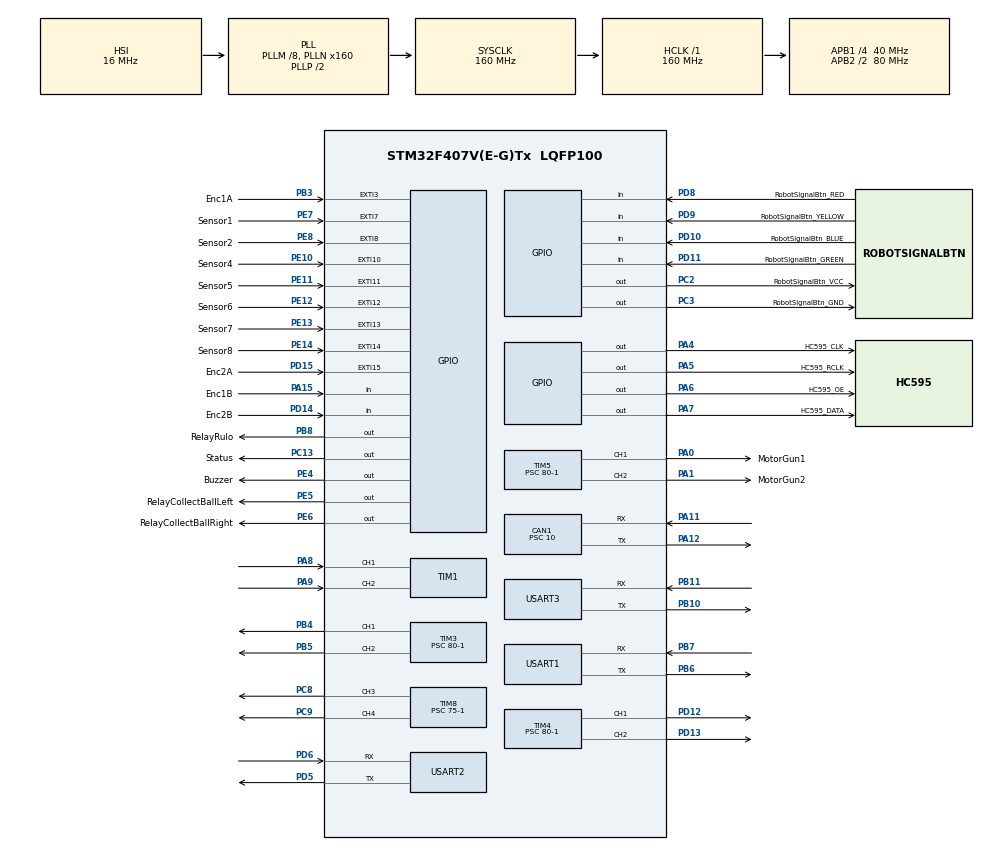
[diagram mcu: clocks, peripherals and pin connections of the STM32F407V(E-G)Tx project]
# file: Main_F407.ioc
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CAN1.BS1=CAN_BS1_2TQ
CAN1.CalculateBaudRate=1000000
CAN1.CalculateTimeBit=1000
CAN1.CalculateTimeQuantum=250.0
CAN1.Prescaler=10
Dma.Request0=USART1_RX
Dma.USART1_RX.0.Direction=DMA_PERIPH_TO_MEMORY
Dma.USART1_RX.0.FIFOMode=DMA_FIFOMODE_DISABLE
Dma.USART1_RX.0.Instance=DMA2_Stream2
Dma.USART1_RX.0.MemDataAlignment=DMA_MDATAALIGN_BYTE
Dma.USART1_RX.0.MemInc=DMA_MINC_ENABLE
Dma.USART1_RX.0.Mode=DMA_CIRCULAR
Dma.USART1_RX.0.PeriphDataAlignment=DMA_PDATAALIGN_BYTE
Dma.USART1_RX.0.PeriphInc=DMA_PINC_DISABLE
Dma.USART1_RX.0.Priority=DMA_PRIORITY_LOW
FREERTOS.Tasks01=defaultTask,-3,256,StartDefaultTask,Default,NULL,Dynamic,NULL,NULL;TaskInvKine,0,256,InverseKinematic,Default,NULL,Static,TaskInvKineBuffer,TaskInvKineControlBlock;TaskCAN,1,128,CAN_Bus,Default,NULL,Static,TaskCANBuffer,TaskCANControlBlock;TaskActuator,1,128,Actuator,Default,NULL,Dynamic,NULL,NULL;TaskOdometer,0,128,OdometerHandle,Default,NULL,Dynamic,NULL,NULL;TaskProcess,0,256,TaskRunProcess,Default,NULL,Dynamic,NULL,NULL
FREERTOS.configMINIMAL_STACK_SIZE=64
FREERTOS.configUSE_NEWLIB_REENTRANT=1
Mcu.Family=STM32F4
Mcu.Name=STM32F407V(E-G)Tx
Mcu.Package=LQFP100
NVIC.CAN1_RX0_IRQn=true\:5\:0\:false\:false\:true\:true\:true\:true\:true
NVIC.DMA2_Stream2_IRQn=true\:5\:0\:false\:false\:true\:true\:false\:true\:true
NVIC.EXTI15_10_IRQn=true\:5\:0\:false\:false\:true\:true\:true\:true\:true
NVIC.EXTI3_IRQn=true\:5\:0\:false\:false\:true\:true\:true\:true\:true
NVIC.EXTI9_5_IRQn=true\:5\:0\:false\:false\:true\:true\:true\:true\:true
NVIC.PriorityGroup=NVIC_PRIORITYGROUP_4
NVIC.TIM8_TRG_COM_TIM14_IRQn=true\:5\:0\:false\:false\:true\:false\:false\:true\:true
NVIC.TimeBase=TIM8_TRG_COM_TIM14_IRQn
NVIC.TimeBaseIP=TIM14
NVIC.USART1_IRQn=true\:5\:0\:false\:false\:true\:true\:true\:true\:true
NVIC.USART2_IRQn=true\:5\:0\:false\:false\:true\:true\:true\:true\:true
NVIC.USART3_IRQn=true\:5\:0\:false\:false\:true\:true\:true\:true\:true
PA0-WKUP.GPIO_Label=MotorGun1
PA0-WKUP.Signal=S_TIM5_CH1
PA1.GPIO_Label=MotorGun2
PA1.Signal=S_TIM5_CH2
PA11.Mode=CAN_Activate
PA11.Signal=CAN1_RX
PA12.Mode=CAN_Activate
PA12.Signal=CAN1_TX
PA13.Mode=Serial_Wire
PA13.Signal=SYS_JTMS-SWDIO
PA14.Mode=Serial_Wire
PA14.Signal=SYS_JTCK-SWCLK
PA15.GPIO_Label=Enc1B
PA15.GPIO_PuPd=GPIO_PULLUP
PA15.Signal=GPIO_Input
PA4.GPIO_Label=HC595_CLK
PA4.Signal=GPIO_Output
PA5.GPIO_Label=HC595_RCLK
PA5.Signal=GPIO_Output
PA6.GPIO_Label=HC595_OE
PA6.Signal=GPIO_Output
PA7.GPIO_Label=HC595_DATA
PA7.Signal=GPIO_Output
PA8.Signal=S_TIM1_CH1
PA9.Signal=S_TIM1_CH2
PB10.Mode=Asynchronous
PB10.Signal=USART3_TX
PB11.Mode=Asynchronous
PB11.Signal=USART3_RX
PB3.GPIO_Label=Enc1A
PB3.GPIO_ModeDefaultEXTI=GPIO_MODE_IT_RISING
PB3.GPIO_PuPd=GPIO_PULLUP
PB3.Signal=GPXTI3
PB4.Signal=S_TIM3_CH1
PB5.Signal=S_TIM3_CH2
PB6.Mode=Asynchronous
PB6.Signal=USART1_TX
PB7.Mode=Asynchronous
PB7.Signal=USART1_RX
PB8.GPIO_Label=RelayRulo
PB8.Signal=GPIO_Output
PC13-ANTI_TAMP.GPIO_Label=Status
PC13-ANTI_TAMP.Signal=GPIO_Output
PC2.GPIO_Label=RobotSignalBtn_VCC
PC2.Signal=GPIO_Output
PC3.GPIO_Label=RobotSignalBtn_GND
PC3.Signal=GPIO_Output
PC8.Signal=S_TIM8_CH3
PC9.Signal=S_TIM8_CH4
PD10.GPIO_Label=RobotSignalBtn_BLUE
PD10.Signal=GPIO_Input
PD11.GPIO_Label=RobotSignalBtn_GREEN
PD11.Signal=GPIO_Input
PD12.Signal=S_TIM4_CH1
PD13.Signal=S_TIM4_CH2
PD14.GPIO_Label=Enc2B
PD14.GPIO_PuPd=GPIO_PULLUP
PD14.Signal=GPIO_Input
PD15.GPIO_Label=Enc2A
PD15.GPIO_PuPd=GPIO_PULLUP
PD15.Signal=GPXTI15
PD5.Mode=Asynchronous
PD5.Signal=USART2_TX
PD6.Mode=Asynchronous
PD6.Signal=USART2_RX
PD8.GPIO_Label=RobotSignalBtn_RED
PD8.Signal=GPIO_Input
PD9.GPIO_Label=RobotSignalBtn_YELLOW
PD9.Signal=GPIO_Input
PE10.GPIO_Label=Sensor4
PE10.Signal=GPXTI10
PE11.GPIO_Label=Sensor5
PE11.Signal=GPXTI11
PE12.GPIO_Label=Sensor6
PE12.Signal=GPXTI12
PE13.GPIO_Label=Sensor7
PE13.Signal=GPXTI13
PE14.GPIO_Label=Sensor8
PE14.Signal=GPXTI14
PE4.GPIO_Label=Buzzer
PE4.Signal=GPIO_Output
PE5.GPIO_Label=RelayCollectBallLeft
PE5.Signal=GPIO_Output
PE6.GPIO_Label=RelayCollectBallRight
PE6.Signal=GPIO_Output
PE7.GPIO_Label=Sensor1
PE7.Signal=GPXTI7
PE8.GPIO_Label=Sensor2
PE8.Signal=GPXTI8
ProjectManager.HeapSize=0x200
ProjectManager.StackSize=0x400
ProjectManager.TargetToolchain=STM32CubeIDE
RCC.48MHZClocksFreq_Value=80000000
RCC.AHBFreq_Value=160000000
RCC.APB1CLKDivider=RCC_HCLK_DIV4
RCC.APB1Freq_Value=40000000
RCC.APB1TimFreq_Value=80000000
RCC.APB2CLKDivider=RCC_HCLK_DIV2
RCC.APB2Freq_Value=80000000
RCC.APB2TimFreq_Value=160000000
RCC.CortexFreq_Value=160000000
RCC.HCLKFreq_Value=160000000
RCC.HSE_VALUE=8000000
RCC.HSI_VALUE=16000000
RCC.LSE_VALUE=32768
RCC.PLLM=8
RCC.PLLN=160
RCC.SYSCLKFreq_VALUE=160000000
RCC.SYSCLKSource=RCC_SYSCLKSOURCE_PLLCLK
RCC.VCOOutputFreq_Value=320000000
SH.S_TIM1_CH1.0=TIM1_CH1,Encoder_Interface
SH.S_TIM1_CH2.0=TIM1_CH2,Encoder_Interface
SH.S_TIM3_CH1.0=TIM3_CH1,PWM Generation1 CH1
SH.S_TIM3_CH2.0=TIM3_CH2,PWM Generation2 CH2
SH.S_TIM4_CH1.0=TIM4_CH1,PWM Generation1 CH1
SH.S_TIM4_CH2.0=TIM4_CH2,PWM Generation2 CH2
SH.S_TIM5_CH1.0=TIM5_CH1,PWM Generation1 CH1
SH.S_TIM5_CH2.0=TIM5_CH2,PWM Generation2 CH2
SH.S_TIM8_CH3.0=TIM8_CH3,PWM Generation3 CH3
SH.S_TIM8_CH4.0=TIM8_CH4,PWM Generation4 CH4
TIM1.EncoderMode=TIM_ENCODERMODE_TI12
TIM10.Period=65000
TIM10.Prescaler=160-1
TIM3.Channel-PWM\ Generation1\ CH1=TIM_CHANNEL_1
TIM3.Channel-PWM\ Generation2\ CH2=TIM_CHANNEL_2
TIM3.Period=1000-1
TIM3.Prescaler=80-1
TIM4.Channel-PWM\ Generation1\ CH1=TIM_CHANNEL_1
TIM4.Channel-PWM\ Generation2\ CH2=TIM_CHANNEL_2
TIM4.Period=1000-1
TIM4.Prescaler=80-1
TIM5.Channel-PWM\ Generation1\ CH1=TIM_CHANNEL_1
TIM5.Channel-PWM\ Generation2\ CH2=TIM_CHANNEL_2
TIM5.Period=1000-1
TIM5.Prescaler=80-1
TIM8.Channel-PWM\ Generation3\ CH3=TIM_CHANNEL_3
TIM8.Channel-PWM\ Generation4\ CH4=TIM_CHANNEL_4
TIM8.Period=255-1
TIM8.Prescaler=75-1
TIM9.Period=255-1
TIM9.Prescaler=75-1
USART1.VirtualMode=VM_ASYNC
USART2.VirtualMode=VM_ASYNC
USART3.VirtualMode=VM_ASYNC
VP_FREERTOS_VS_CMSIS_V1.Mode=CMSIS_V1
VP_SYS_VS_tim14.Mode=TIM14
VP_TIM10_VS_ClockSourceINT.Mode=Enable_Timer
VP_TIM3_VS_ClockSourceINT.Mode=Internal
VP_TIM4_VS_ClockSourceINT.Mode=Internal
VP_TIM5_VS_ClockSourceINT.Mode=Internal
VP_TIM8_VS_ClockSourceINT.Mode=Internal
VP_TIM9_VS_ClockSourceINT.Mode=Internal
board=custom

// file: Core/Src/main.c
/* USER CODE BEGIN Header */
/**
 ******************************************************************************
 * @file           : main.c
 * @brief          : Main program body
 ******************************************************************************
 * @attention
 *
 * Copyright (c) 2023 STMicroelectronics.
 * All rights reserved.
 *
 * This software is licensed under terms that can be found in the LICENSE file
 * in the root directory of this software component.
 * If no LICENSE file comes with this software, it is provided AS-IS.
 *
 ******************************************************************************
 */
/* USER CODE END Header */
#include "main.h"
#include "cmsis_os.h"

/* USER CODE BEGIN Includes */
#include "CAN_Control.h"
#include "CAN_FuncHandle.h"
#include "stdbool.h"
#include "PID.h"
#include "Flag.h"
#include "InverseKinematic.h"
#include "SwerveModule.h"
#include "string.h"
#include "Gamepad.h"
#include "RB1ActuatorValve.h"
#include "MainF4Robot1App.h"
#include "ActuatorGun.h"
#include "Robot1_Sensor.h"
#include "Robot1_InShootBallTime.h"
#include "PositionControl.h"
#include "Encoder.h"
/* USER CODE END Includes */

/* USER CODE BEGIN PTD */
typedef enum MainEvent {
	MEVT_GET_NODE_SPEED_ANGLE,
} MainEvent;
/* USER CODE END PTD */

CAN_HandleTypeDef hcan1;

TIM_HandleTypeDef htim1;
TIM_HandleTypeDef htim3;
TIM_HandleTypeDef htim4;
TIM_HandleTypeDef htim5;
TIM_HandleTypeDef htim8;
TIM_HandleTypeDef htim9;
TIM_HandleTypeDef htim10;

UART_HandleTypeDef huart1;
UART_HandleTypeDef huart2;
UART_HandleTypeDef huart3;
DMA_HandleTypeDef hdma_usart1_rx;

osThreadId defaultTaskHandle;
osThreadId TaskInvKineHandle;
uint32_t TaskInvKineBuffer[ 256 ];
osStaticThreadDef_t TaskInvKineControlBlock;
osThreadId TaskCANHandle;
uint32_t TaskCANBuffer[ 128 ];
osStaticThreadDef_t TaskCANControlBlock;
osThreadId TaskActuatorHandle;
osThreadId TaskOdometerHandle;
osThreadId TaskProcessHandle;
/* USER CODE BEGIN PV */

CAN_DEVICE_ID targetID = CANCTRL_DEVICE_MOTOR_CONTROLLER_1;
PID_Param pid;
PID_type type = PID_BLDC_SPEED;

CAN_MODE_ID Mode_ID = CANCTRL_MODE_MOTOR_SPEED_ANGLE;
PID_Param targetPID = {
		.deltaT = 0.001,
		.kP = 10,
		.kI = 10,
		.kD = 1,
		.alpha = 1,
};
PID_type pidType = PID_BLDC_SPEED;
uint8_t encEnb, encDis;
CAN_SpeedBLDC_AngleDC nodeSpeedAngle[3] = { 0 };

uint8_t UARTRX3_Buffer[9];
uint8_t DataTayGame[9];

float Xleft, Yleft;
float Xright;

_GamePad GamePad;
uint32_t gamepadRxIsBusy = 0;

float DeltaYR, DeltaYL, DeltaX;
uint8_t Run = 0, resetParam, breakProtect;
float uControlX, uControlY, uControlTheta;
uint8_t stateRun = 0, steadycheck;
uint8_t xaDay;
uint8_t ssCheck, stateChange, rst, Manual;
uint8_t numOfBall = 0;
bool safetyMode = false;
//////////////////////////////////////////////////////////////////////////////////////////////////////////

uint8_t step = 0;
uint8_t angle_PID_Cycle;
////////////MPU//////////////
uint8_t mpu[10];
uint8_t send_mpu;
int16_t angle;
float a_Now;
float angle_Rad;
uint8_t reset_MPU;

///////////PID MPU///////////////
PID_Param pid_Angle;
uint8_t use_pidTheta;
float TargetTheta, TargetTheta_Degree;
//////////Floating Enc///////
uint8_t reset_ENC;
Encoder_t FloatingEnc;
int floatingEncCount;

//////////Control Signal/////
float u, v, r;

//////////Process ///////////
uint8_t RunProcess;
float chasis_Vector_TargetSpeed;
uint8_t angle_Accel_Flag;
float PreTargetAngle;
float process_AutoChose;
float process_AutoChose_Count;
float process_SubState;
uint8_t process_GetBall_State;
uint8_t process_SSCheck;
int process_Count;
ValveProcessName valveProcessName = 0;
int PlusControl;
float V_want = 0;
uint8_t Blue = 0, Red = 0, Retry = 0;
///////////////////////////////////////Quy Hoach Quy Dao///////////////////////////////////////////
trajec_Param trajecTheta;
//////////////////////////////////////////////////////////////////////////////////////////////////////////

uint32_t nodeSwerveSetHomeComplete = 0;
int gunCount1, gunCount2;
QueueHandle_t qShoot;
bool testTick = false;

#define SETHOME_FLAG_GROUP nodeSwerveSetHomeComplete
void nodeHome_SetFlag(CAN_DEVICE_ID e) {
	SETFLAG(SETHOME_FLAG_GROUP, e);
}
bool nodeHome_CheckFlag(CAN_DEVICE_ID e) {
	return CHECKFLAG(SETHOME_FLAG_GROUP, e);
}
void nodeHome_ClearFlag(CAN_DEVICE_ID e) {
	CLEARFLAG(SETHOME_FLAG_GROUP, e);
}

/* USER CODE END PV */

void SystemClock_Config(void);
static void MX_GPIO_Init(void);
static void MX_DMA_Init(void);
static void MX_CAN1_Init(void);
static void MX_USART3_UART_Init(void);
static void MX_TIM1_Init(void);
static void MX_TIM10_Init(void);
static void MX_USART1_UART_Init(void);
static void MX_USART2_UART_Init(void);
static void MX_TIM5_Init(void);
static void MX_TIM9_Init(void);
static void MX_TIM4_Init(void);
static void MX_TIM3_Init(void);
static void MX_TIM8_Init(void);
void StartDefaultTask(void const * argument);
void InverseKinematic(void const * argument);
void CAN_Bus(void const * argument);
void Actuator(void const * argument);
void OdometerHandle(void const * argument);
void TaskRunProcess(void const * argument);

/* USER CODE BEGIN 0 */

/*=============================== CAN ===============================*/
void HAL_CAN_RxFifo0MsgPendingCallback(CAN_HandleTypeDef *hcan) {
	HAL_CAN_DeactivateNotification(hcan, CAN_IT_RX_FIFO0_MSG_PENDING);
	CAN_MODE_ID modeID = canctrl_Receive_2(hcan, CAN_RX_FIFO0);
	BaseType_t HigherPriorityTaskWoken = pdFALSE;
	xTaskNotifyFromISR(TaskCANHandle, modeID, eSetValueWithOverwrite, &HigherPriorityTaskWoken);
	portYIELD_FROM_ISR(HigherPriorityTaskWoken);
}
void HAL_CAN_RxFifo1MsgPendingCallback(CAN_HandleTypeDef *hcan) {
	HAL_CAN_DeactivateNotification(hcan, CAN_IT_RX_FIFO1_MSG_PENDING);
	CAN_MODE_ID modeID = canctrl_Receive_2(hcan, CAN_RX_FIFO1);
	BaseType_t HigherPriorityTaskWoken = pdFALSE;
	xTaskNotifyFromISR(TaskCANHandle, modeID, eSetValueWithOverwrite, &HigherPriorityTaskWoken);
	portYIELD_FROM_ISR(HigherPriorityTaskWoken);
}
void CAN_Init() {
	HAL_CAN_Start(&hcan1);
	HAL_CAN_ActivateNotification(&hcan1,
	CAN_IT_RX_FIFO0_MSG_PENDING | CAN_IT_RX_FIFO1_MSG_PENDING);
	canctrl_Filter_Mask16(&hcan1, CANCTRL_MODE_SET_HOME << 5,
			CANCTRL_MODE_ROBOT_ERROR << 5,
			CANCTRL_MODE_SET_HOME << 5,
			CANCTRL_MODE_ROBOT_ERROR << 5, 0,
			CAN_RX_FIFO0);
}

void setHomeComplete() {
	HAL_GPIO_WritePin(Buzzer_GPIO_Port, Buzzer_Pin, GPIO_PIN_SET);
	osDelay(100);
	HAL_GPIO_WritePin(Buzzer_GPIO_Port, Buzzer_Pin, GPIO_PIN_RESET);
}

void robotErrorHandler(CAN_DEVICE_ID targetID)
{

	while(1){
		safetyMode = 1;
		if(targetID == CANCTRL_DEVICE_MOTOR_CONTROLLER_1){
			HAL_GPIO_WritePin(Buzzer_GPIO_Port, Buzzer_Pin, 1);
			osDelay(50);
			HAL_GPIO_WritePin(Buzzer_GPIO_Port, Buzzer_Pin, 0);
			osDelay(1000);
		}
		else if(targetID == CANCTRL_DEVICE_MOTOR_CONTROLLER_2){
			for(uint8_t i = 0; i < 2; i++){
				HAL_GPIO_WritePin(Buzzer_GPIO_Port, Buzzer_Pin, 1);
				osDelay(100);
				HAL_GPIO_WritePin(Buzzer_GPIO_Port, Buzzer_Pin, 0);
			}
			osDelay(1000);
		}
		else if(targetID == CANCTRL_DEVICE_MOTOR_CONTROLLER_3){
			for(uint8_t i = 0; i < 3; i++){
				HAL_GPIO_WritePin(Buzzer_GPIO_Port, Buzzer_Pin, 1);
				osDelay(100);
				HAL_GPIO_WritePin(Buzzer_GPIO_Port, Buzzer_Pin, 0);
			}
			osDelay(1000);
		}
	}
}

void handleFunctionCAN(CAN_MODE_ID mode, CAN_DEVICE_ID targetID) {
	switch (mode) {
		case CANCTRL_MODE_SET_HOME:
			nodeHome_SetFlag(targetID);
			// @formatter:off
//			if(nodeHome_CheckFlag(
//					  1 << CANCTRL_DEVICE_MOTOR_CONTROLLER_1
//					| 1 << CANCTRL_DEVICE_MOTOR_CONTROLLER_2
//					| 1 << CANCTRL_DEVICE_MOTOR_CONTROLLER_3
//					| 1 << CANCTRL_DEVICE_MOTOR_CONTROLLER_4
//					))
			if(nodeSwerveSetHomeComplete == 14)
				setHomeComplete();
																		// @formatter:on
			break;
		case CANCTRL_MODE_ROBOT_ERROR:
			robotErrorHandler(targetID);
			break;
		case CANCTRL_MODE_UNTANGLE_WIRE:
			canfunc_SetBoolValue(1, CANCTRL_MODE_UNTANGLE_WIRE);
			while (canctrl_Send(&hcan1, targetID) != HAL_OK);
			break;
		default:
			break;
	}

}

void HAL_CAN_ErrorCallback(CAN_HandleTypeDef *hcan) {
	HAL_GPIO_WritePin(Buzzer_GPIO_Port, Buzzer_Pin, GPIO_PIN_SET);
	while (1);
}
/*=============================== UART ===============================*/
uint8_t YawHandle;
uint8_t AngleData[5];
int CurrAngle;

char ds[12];
uint8_t uart2_ds[5], ds_ind, ds_cnt, ds_flg;
uint8_t UARTRX3_Buffer[9];
bool phatHienLuaTrai = false;
bool phatHienLuaPhai = false;
bool phatHienBongTrai = false;
bool phatHienBongPhai = false;
void Receive(uint8_t *DataArray) {
	uint8_t *pInt = NULL;
	if (DataArray[4] == 13) {
		pInt = (uint8_t*) &CurrAngle;
		for (uint8_t i = 0; i < 4; i++) {
			*(pInt + i) = DataArray[i];
		}
	}
	memset(DataArray, 0, 5);
	YawHandle = 1;
}

void HAL_UART_RxCpltCallback(UART_HandleTypeDef *huart) {
	appintf_ReceiveDataInterrupt(huart);
	if (huart->Instance == USART3) {
		gamepadRxIsBusy = 1;
		int ViTriData = -1;
		for (int i = 0; i <= 8; ++i) {
			if (UARTRX3_Buffer[i] == 0xAA) {
				ViTriData = i;
			}
		}
		if (ViTriData != -1) {
			int cnt = 0;
			while (cnt < 9) {
				DataTayGame[cnt] = UARTRX3_Buffer[ViTriData];
				++ViTriData;
				if (ViTriData >= 9) {
					ViTriData = 0;
				}
				++cnt;
			}

			GamepPadHandle(&GamePad, DataTayGame);

		}
		else {
			GamePad.Status = 0;
		}
		if (!gamepadRxIsBusy)
			HAL_UART_Receive_IT(&huart3, (uint8_t*) UARTRX3_Buffer, 9);

	}
}

void HAL_UART_ErrorCallback(UART_HandleTypeDef *huart) {
	__HAL_UART_CLEAR_OREFLAG(huart);
	memset(UARTRX3_Buffer, 0, sizeof(UARTRX3_Buffer));
	HAL_UART_Receive_IT(&huart3, (uint8_t*) UARTRX3_Buffer, 9);
	__HAL_UART_DISABLE(huart);
}
/*=============================== GPIO EXTI ===============================*/
void HAL_GPIO_EXTI_Callback(uint16_t GPIO_Pin) {

	if (GPIO_Pin == Enc1A_Pin) {
		if (HAL_GPIO_ReadPin(Enc1B_GPIO_Port, Enc1B_Pin)) {
			RB1_EncGun1_IncreaseCount();
		}
		else
			RB1_EncGun1_DecreaseCount();
		return;
	}
	if (GPIO_Pin == Enc2A_Pin) {
		if (HAL_GPIO_ReadPin(Enc2B_GPIO_Port, Enc2B_Pin)) {
			RB1_EncGun2_DecreaseCount();
		}
		else
			RB1_EncGun2_IncreaseCount();
		return;
	}
}

float absf(float num)
{
	if (num >= 0)
		return num;
	else
		return num * -1;
}
///////////////////////////MPU//////////////////////////
#define DELTA_T 0.05
void Get_MPU_Angle()
{
	send_mpu = 'z';
	HAL_UART_Transmit(&huart1, &send_mpu, 1, 1);
	angle = mpu[0] << 8 | mpu[1];
	a_Now = angle;
}

void Reset_MPU_Angle()
{
	send_mpu = 'a';
	HAL_UART_Transmit(&huart1, &send_mpu, 1, 1);

}
/////////////////////Process///////////////////
void process_Init()
{
	////////PID/////////
	pid_Angle.kP = 0.5;
	pid_Angle.kI = 0;
	pid_Angle.kD = 0;
	pid_Angle.alpha = 0;
	pid_Angle.deltaT = DELTA_T;
	pid_Angle.u_AboveLimit = 5;
	pid_Angle.u_BelowLimit = -5;
	pid_Angle.kB = 1 / DELTA_T;

	process_AutoChose = 0;

	encoder_Init(&FloatingEnc, &htim1, 200, DELTA_T);
//	encoder_Init(&FloatingEnc, &htim2, 200, DELTA_T);

}

void process_PD_OnStrainghtPath()
{
	pid_Angle.kP = 1.2;
	pid_Angle.kI = 0;
	pid_Angle.kD = 0;
	pid_Angle.alpha = 0;
	pid_Angle.deltaT = DELTA_T;
	pid_Angle.u_AboveLimit = 5;
	pid_Angle.u_BelowLimit = -5;
	pid_Angle.kB = 1 / DELTA_T;
}

void process_PD_OnTrajecPath()
{
	pid_Angle.kP = 0.5;
	pid_Angle.kI = 0;
	pid_Angle.kD = 0;
	pid_Angle.alpha = 0;
	pid_Angle.deltaT = DELTA_T;
	pid_Angle.u_AboveLimit = 5;
	pid_Angle.u_BelowLimit = -5;
	pid_Angle.kB = 1 / DELTA_T;
}

void process_PD_Auto_Chose(float Target, float Current)
{
	if (process_AutoChose == 0)
			{
		if (absf(Target - Current) < 8 * M_PI / 180)
				{
			process_AutoChose_Count++;
		}
		else {
			process_AutoChose_Count = 0;
		}
	}

	if (process_AutoChose_Count > 15)
			{
		process_AutoChose_Count = 0;
		process_AutoChose = 1;
	}

	if (process_AutoChose == 1)
			{
		process_PD_OnStrainghtPath();
	}
	else {
		process_PD_OnTrajecPath();
	}
}
void process_SetFloatingEnc()
{
	floatingEncCount = encoder_GetFloatingDis(&FloatingEnc);
}

void process_ResetFloatingEnc()
{
	encoder_ResetCount(&FloatingEnc);
	floatingEncCount = 0;
}

void process_Accel_FloatingEnc3(float Angle, float maxSpeed, float s, float accel, float TargetAngle, float RotateTime)
{
	if (process_SubState == 0)
			{
		trajecPlan_SetParam(&trajecTheta, angle_Rad, TargetAngle * M_PI / 180, RotateTime, 0, 0);
		process_ResetFloatingEnc();
		use_pidTheta = 1;
		process_SubState = 1;
	}
	else {

		if ((floatingEncCount < 500) && (chasis_Vector_TargetSpeed < maxSpeed))
				{
			chasis_Vector_TargetSpeed += accel;
		}
		if ((floatingEncCount > 500) && (floatingEncCount < (s - 500)))
				{
			chasis_Vector_TargetSpeed = maxSpeed;
		}
		if (floatingEncCount > (s - 500) && floatingEncCount < (s - 400)) {
			chasis_Vector_TargetSpeed = maxSpeed / 2;
		}
		if (floatingEncCount > (s - 400)) {
			chasis_Vector_TargetSpeed -= accel;
		}
			if ((chasis_Vector_TargetSpeed <= 0) || (floatingEncCount > s))
			{

				chasis_Vector_TargetSpeed = 0;
				process_ResetFloatingEnc();
				r = 0;
				u = 0;
				v = 0;
				use_pidTheta = 0;
				process_SubState = 0;
//				step += 1;

		}
		else {
			u = cos(Angle * M_PI / 180) * chasis_Vector_TargetSpeed;
			v = sin(Angle * M_PI / 180) * chasis_Vector_TargetSpeed;

		}
	}

}

void process_Accel_FloatingEnc4(float Angle, float maxSpeed, float s, float accel, float TargetAngle, float RotateTime)
{
	if (process_SubState == 0)
			{
		trajecPlan_SetParam(&trajecTheta, angle_Rad, TargetAngle * M_PI / 180, RotateTime, 0, 0);
		process_ResetFloatingEnc();
		use_pidTheta = 1;
		process_SubState = 1;
	}
	else {
		if(chasis_Vector_TargetSpeed>maxSpeed)chasis_Vector_TargetSpeed=maxSpeed;
		if ((floatingEncCount < 500) && (chasis_Vector_TargetSpeed < maxSpeed))
				{
			chasis_Vector_TargetSpeed += accel;
		}
		if ((floatingEncCount > 500) && (floatingEncCount < (s - 500)))
				{
			chasis_Vector_TargetSpeed = maxSpeed;
		}
		if (floatingEncCount > (s - 500) && floatingEncCount < (s - 400)) {
			chasis_Vector_TargetSpeed = maxSpeed / 2;
		}
		if (floatingEncCount > (s - 400)) {
			chasis_Vector_TargetSpeed -= accel*5;
		}
		if ((chasis_Vector_TargetSpeed <= 0) || (floatingEncCount > s))
		{
			u = 0;
			v = 0;
			if (absf(trajecTheta.Pf-angle_Rad)<2*M_PI/180)
			{
				process_SSCheck ++;
			}else{
				process_SSCheck = 0;
			}

			if(process_SSCheck > 10)
			{
			chasis_Vector_TargetSpeed = 0;
			process_ResetFloatingEnc();
			r = 0;
			process_SSCheck = 0;
			use_pidTheta = 0;
			process_SubState = 0;
			step += 1;
			}
		}
		else {
			u = cos(Angle * M_PI / 180) * chasis_Vector_TargetSpeed;
			v = sin(Angle * M_PI / 180) * chasis_Vector_TargetSpeed;

		}
	}

}

void process_Accel_FloatingEnc5(float Angle, float maxSpeed, float s, float accel, float TargetAngle, float RotateTime)
{
	if (process_SubState == 0)
			{
		trajecPlan_SetParam(&trajecTheta, angle_Rad, TargetAngle * M_PI / 180, RotateTime, 0, 0);
		process_ResetFloatingEnc();
		use_pidTheta = 1;
		process_SubState = 1;
	}
	else {

		if ((floatingEncCount < 500) && (chasis_Vector_TargetSpeed < maxSpeed))
				{
			chasis_Vector_TargetSpeed += accel;
		}
		if ((floatingEncCount > 500) && (floatingEncCount < (s - 500)))
				{
			chasis_Vector_TargetSpeed = maxSpeed;
		}
		if (floatingEncCount > (s - 500) && floatingEncCount < (s - 400)) {
			chasis_Vector_TargetSpeed = maxSpeed / 2;
		}
		if (floatingEncCount > (s - 400)) {
			chasis_Vector_TargetSpeed -= accel*5;
		}if(floatingEncCount > (s - 150)) {
			use_pidTheta = 0;
			r = 0;
		}
		if ((chasis_Vector_TargetSpeed <= 0) || (floatingEncCount > s))
		{
			u = 0;
			v = 0;
			if (absf(trajecTheta.Pf-angle_Rad)<2*M_PI/180)
			{
				process_SSCheck ++;
			}else{
				process_SSCheck = 0;
			}

			if(process_SSCheck > 10)
			{
			chasis_Vector_TargetSpeed = 0;
			process_ResetFloatingEnc();
			r = 0;
			process_SSCheck = 0;
			use_pidTheta = 0;
			process_SubState = 0;
			step += 1;
			}
		}
		else {
			u = cos(Angle * M_PI / 180) * chasis_Vector_TargetSpeed;
			v = sin(Angle * M_PI / 180) * chasis_Vector_TargetSpeed;

		}
	}

}
float AngleNow,AngleTargetPre,AngleTarget,AngleFlag;
void process_Accel_FloatingEnc6(float Angle,float maxSpeed,float s,float accel,float TargetAngle,float RotateTime,float AccelAngle)
{
	if (process_SubState == 0)
	{
		AngleTarget = Angle;
		if (AngleTarget > AngleTargetPre){
			AngleFlag = 1;
		}else{
			AngleFlag = 2;
		}
		trajecPlan_SetParam(&trajecTheta, angle_Rad, TargetAngle*M_PI/180, RotateTime, 0, 0);
		process_ResetFloatingEnc();
		process_SubState = 1;
	}else{
		if(AngleFlag == 1)
		{
			AngleNow += AccelAngle;
			if (AngleNow > AngleTarget)
			{
				AngleNow = AngleTarget;
			}
		}else if (AngleFlag == 2){
			AngleNow -= AccelAngle;
			if (AngleNow < AngleTarget)
			{
				AngleNow = AngleTarget;
			}
		}

		AngleTargetPre = AngleTarget;

		use_pidTheta = 1;
		if ((floatingEncCount < 500)&&(chasis_Vector_TargetSpeed<maxSpeed))
		{
			chasis_Vector_TargetSpeed += accel;
		}
		if ((floatingEncCount > 500)&&(floatingEncCount < (s - 500)))
		{
			chasis_Vector_TargetSpeed = maxSpeed;
		}
		if (floatingEncCount > (s - 500)&&floatingEncCount < (s - 400)){
			chasis_Vector_TargetSpeed = maxSpeed/2		;
			}
		if (floatingEncCount > (s - 400)){
			chasis_Vector_TargetSpeed -= accel ;
		}
//		if (floatingEncCount < (s - 1)){
//			use_pidTheta = 0;
//			r = 0;
//		}

		if ((chasis_Vector_TargetSpeed<=0)||(floatingEncCount > s))
		{
			chasis_Vector_TargetSpeed = 0;
			process_ResetFloatingEnc();
			r = 0;
			u = 0;
			v = 0;
			use_pidTheta = 0;
			process_SubState = 0;
			step += 1;
		}else{
			u = cos(AngleNow*M_PI/180)*chasis_Vector_TargetSpeed ;
			v = sin(AngleNow*M_PI/180)*chasis_Vector_TargetSpeed ;

		}
	}

}

void process_Accel_FloatingEnc9(float Angle,float maxSpeed,float s,float accel,float TargetAngle,float RotateTime,float AccelAngle)
{
	if (process_SubState == 0)
	{
		AngleTarget = Angle;
		if (AngleTarget > AngleTargetPre){
			AngleFlag = 1;
		}else{
			AngleFlag = 2;
		}
		trajecPlan_SetParam(&trajecTheta, angle_Rad, TargetAngle*M_PI/180, RotateTime, 0, 0);
		process_ResetFloatingEnc();
		process_SubState = 1;
	}else{
		if(AngleFlag == 1)
		{
			AngleNow += AccelAngle;
			if (AngleNow > AngleTarget)
			{
				AngleNow = AngleTarget;
			}
		}else if (AngleFlag == 2){
			AngleNow -= AccelAngle;
			if (AngleNow < AngleTarget)
			{
				AngleNow = AngleTarget;
			}
		}

		AngleTargetPre = AngleTarget;

		use_pidTheta = 1;
		if ((floatingEncCount < 500)&&(chasis_Vector_TargetSpeed<maxSpeed))
		{
			chasis_Vector_TargetSpeed += accel;
		}
		if ((floatingEncCount > 500)&&(floatingEncCount < (s - 500)))
		{
			chasis_Vector_TargetSpeed = maxSpeed;
		}
		if (floatingEncCount > (s - 500)&&floatingEncCount < (s - 400)){
			chasis_Vector_TargetSpeed = maxSpeed/2		;
			}
		if (floatingEncCount > (s - 400)){
			chasis_Vector_TargetSpeed -= accel ;
		}
		if (floatingEncCount > (s - 150)){
			use_pidTheta = 0;
			r = 0;
		}

		if ((chasis_Vector_TargetSpeed<=0)||(floatingEncCount > s))
		{
			chasis_Vector_TargetSpeed = 0;
			process_ResetFloatingEnc();
			r = 0;
			u = 0;
			v = 0;
			use_pidTheta = 0;
			process_SubState = 0;
			step += 1;
		}else{
			u = cos(AngleNow*M_PI/180)*chasis_Vector_TargetSpeed ;
			v = sin(AngleNow*M_PI/180)*chasis_Vector_TargetSpeed ;

		}
	}

}

void process_Accel_FloatingEnc7(float Angle,float maxSpeed,float s,float accel,float TargetAngle,float RotateTime,float AccelAngle)
{
	if (process_SubState == 0)
	{
		AngleTarget = Angle;
		if (AngleTarget > AngleTargetPre){
			AngleFlag = 1;
		}else{
			AngleFlag = 2;
		}
		trajecPlan_SetParam(&trajecTheta, angle_Rad, TargetAngle*M_PI/180, RotateTime, 0, 0);
		process_ResetFloatingEnc();
		process_SubState = 1;
	}else{
		if(AngleFlag == 1)
		{
			AngleNow += AccelAngle;
			if (AngleNow > AngleTarget)
			{
				AngleNow = AngleTarget;
			}
		}else if (AngleFlag == 2){
			AngleNow -= AccelAngle;
			if (AngleNow < AngleTarget)
			{
				AngleNow = AngleTarget;
			}
		}

		AngleTargetPre = AngleTarget;

		use_pidTheta = 1;
		if ((floatingEncCount < 500)&&(chasis_Vector_TargetSpeed<maxSpeed))
		{
			chasis_Vector_TargetSpeed += accel;
		}
		if ((floatingEncCount > 500)&&(floatingEncCount < (s - 500)))
		{
			chasis_Vector_TargetSpeed = maxSpeed;
		}
		if (floatingEncCount > (s - 500)&&floatingEncCount < (s - 400)){
			chasis_Vector_TargetSpeed = maxSpeed/2		;
			}
		if (floatingEncCount > (s - 400)){
			chasis_Vector_TargetSpeed -= accel ;
		}
//		if (floatingEncCount < (s - 1)){
//			use_pidTheta = 0;
//			r = 0;
//		}

		if ((chasis_Vector_TargetSpeed<=0)||(floatingEncCount > s))
		{
			u = 0;
			v = 0;
			if (absf(trajecTheta.Pf-angle_Rad)<4*M_PI/180)
			{
				process_SSCheck ++;
			}else{
				process_SSCheck = 0;
			}

			if(process_SSCheck > 10)
			{
			chasis_Vector_TargetSpeed = 0;
			process_ResetFloatingEnc();
			r = 0;
			process_SSCheck = 0;
			use_pidTheta = 0;
			process_SubState = 0;
			step += 1;
			}
		}else{
			u = cos(AngleNow*M_PI/180)*chasis_Vector_TargetSpeed ;
			v = sin(AngleNow*M_PI/180)*chasis_Vector_TargetSpeed ;

		}
	}

}

void process_Accel_FloatingEnc8(float Angle,float maxSpeed,float s,float accel,float sDeaccel,float deaccel,float TargetAngle,float RotateTime,float AccelAngle)
{
	if (process_SubState == 0)
	{
		AngleTarget = Angle;
		if (AngleTarget > AngleTargetPre){
			AngleFlag = 1;
		}else{
			AngleFlag = 2;
		}
		trajecPlan_SetParam(&trajecTheta, angle_Rad, TargetAngle*M_PI/180, RotateTime, 0, 0);
		process_ResetFloatingEnc();
		process_SubState = 1;
	}else{
		if(AngleFlag == 1)
		{
			AngleNow += AccelAngle;
			if (AngleNow > AngleTarget)
			{
				AngleNow = AngleTarget;
			}
		}else if (AngleFlag == 2){
			AngleNow -= AccelAngle;
			if (AngleNow < AngleTarget)
			{
				AngleNow = AngleTarget;
			}
		}

		AngleTargetPre = AngleTarget;

		use_pidTheta = 1;
		if ((floatingEncCount < 500)&&(chasis_Vector_TargetSpeed<maxSpeed))
		{
			chasis_Vector_TargetSpeed += accel;
		}
		if ((floatingEncCount > 500)&&(floatingEncCount < (sDeaccel)))
		{
			chasis_Vector_TargetSpeed = maxSpeed;
		}
		if (floatingEncCount > sDeaccel){
			chasis_Vector_TargetSpeed -= deaccel;
			}
		if (chasis_Vector_TargetSpeed < 0.2){
			chasis_Vector_TargetSpeed = 0.2 ;
		}
//		if (floatingEncCount < (s - 1)){
//			use_pidTheta = 0;
//			r = 0;
//		}

		if ((floatingEncCount > s))
		{
			u = 0;
			v = 0;
			if (absf(trajecTheta.Pf-angle_Rad)<5*M_PI/180)
			{
				process_SSCheck ++;
			}else{
				process_SSCheck = 0;
			}

			if(process_SSCheck > 10)
			{
			chasis_Vector_TargetSpeed = 0;
			process_ResetFloatingEnc();
			r = 0;
			process_SSCheck = 0;
			use_pidTheta = 0;
			process_SubState = 0;
			step += 1;
			}
		}else{
			u = cos(AngleNow*M_PI/180)*chasis_Vector_TargetSpeed ;
			v = sin(AngleNow*M_PI/180)*chasis_Vector_TargetSpeed ;

		}
	}

}
void process_RunByAngle(float Angle, float speed)
{
	u = cos(Angle * M_PI / 180) * speed;
	v = sin(Angle * M_PI / 180) * speed;
}

void process_RunByAngle2(float Angle, float speed, float time)
{
	use_pidTheta = 1;
	process_Count++;
	process_RunByAngle(Angle, speed);
	if (process_Count > time/50)
	{
		process_RunByAngle(Angle, 0);

		if(absf(trajecTheta.Pf-angle_Rad)<2*M_PI/180)
		{
			process_SSCheck++;
		}else{
			process_SSCheck = 0;
		}

		if(process_SSCheck>10)
		{
			process_Count = 0;
			process_ResetFloatingEnc();
			process_SSCheck =0;
			use_pidTheta = 0;
			step += 1;
			r = 0;
//			process_RunByAngle(Angle, 0);
		}
	}
}
void process_RunByAngle3(float Angle, float speed, float s)
{
	if(process_SSCheck == 0)
	{
		process_ResetFloatingEnc();
		process_SSCheck = 1;
		use_pidTheta = 1;
	}
	else if(process_SSCheck == 1)
	{
		process_RunByAngle(Angle, speed);
		if(floatingEncCount >= s -100)
		{
			use_pidTheta = 0;
			r = 0;

		}
		if(floatingEncCount >= s)
		{
			process_RunByAngle(Angle, 0);
			process_ResetFloatingEnc();
			process_SSCheck =0;
//			step += 1;

		}
	}
}

void process_Signal_RotationMatrixTransform(float u, float v, float r)
{
	uControlX = u * cos(angle_Rad) - v * sin(angle_Rad);
	uControlY = u * sin(angle_Rad) + v * cos(angle_Rad);
	uControlTheta = r;
}

void process_Signal_RotationMatrixTransform2(float u, float v, float r)
{
	float offset_Angle = trajecTheta.Pf;
	uControlX = -(u * cos(angle_Rad + offset_Angle) - v * sin(angle_Rad + offset_Angle));
	uControlY = -(u * sin(angle_Rad + offset_Angle) + v * cos(angle_Rad + offset_Angle));
	uControlTheta = r;
}
void process_Signal_RotationMatrixTransform3(float u, float v, float r)
{
	float offset_Angle = trajecTheta.Pf;
	uControlX = (u * cos(angle_Rad + offset_Angle) - v * sin(angle_Rad + offset_Angle));
	uControlY = (u * sin(angle_Rad + offset_Angle) + v * cos(angle_Rad + offset_Angle));
	uControlTheta = r;
}

void process_Error(uint8_t error)
{
	if (error == 1)
			{
		HAL_GPIO_WritePin(Buzzer_GPIO_Port, Buzzer_Pin, GPIO_PIN_SET);
		HAL_GPIO_TogglePin(Status_GPIO_Port, Status_Pin);
	}
	else if (error == 0)
			{
		HAL_GPIO_WritePin(Buzzer_GPIO_Port, Buzzer_Pin, GPIO_PIN_RESET);
		HAL_GPIO_WritePin(Status_GPIO_Port, Status_Pin, GPIO_PIN_RESET);
	}
}

void process_PhatHienLuaTrai() {
	phatHienLuaTrai = true;
}

void process_PhatHienLuaPhai() {
	phatHienLuaPhai = true;
}

bool process_ThucHienGapLua() {

	bool gapLuaThanhCong = false;
		Sensor_t camBienLuaTrai = RB1_GetSensor(RB1_SENSOR_ARM_LEFT);
		Sensor_t camBienLuaPhai = RB1_GetSensor(RB1_SENSOR_ARM_RIGHT);

		if (HAL_GPIO_ReadPin(camBienLuaPhai.sensorPort, camBienLuaPhai.sensorPin)) {
			gapLuaThanhCong = true;
		}

	return gapLuaThanhCong;
}
bool process_ThucHienGapLua1() {

	bool gapLuaThanhCong = false;
		Sensor_t camBienLuaTrai = RB1_GetSensor(RB1_SENSOR_ARM_LEFT);
		Sensor_t camBienLuaPhai = RB1_GetSensor(RB1_SENSOR_ARM_RIGHT);

		if (HAL_GPIO_ReadPin(camBienLuaTrai.sensorPort, camBienLuaTrai.sensorPin)) {
			gapLuaThanhCong = true;
		}

	return gapLuaThanhCong;
}
bool process_ThucHienGapLua2() {

	bool gapLuaThanhCong = false;
		Sensor_t camBienLuaTrai = RB1_GetSensor(RB1_SENSOR_ARM_LEFT);
		Sensor_t camBienLuaPhai = RB1_GetSensor(RB1_SENSOR_ARM_RIGHT);

		if (HAL_GPIO_ReadPin(camBienLuaTrai.sensorPort, camBienLuaTrai.sensorPin) || HAL_GPIO_ReadPin(camBienLuaPhai.sensorPort, camBienLuaPhai.sensorPin)) {
			gapLuaThanhCong = true;
		}

	return gapLuaThanhCong;
}
void process_RiceAppRoach()
{
	if(process_SubState == 0)
	{
		use_pidTheta = 1;
		if((process_ThucHienGapLua1() == true) || GamePad.Down){
			process_Error(1);
			process_SubState = 1;
		}
	}
	else if(process_SubState == 1){
		process_Error(0);
		Manual = 1;
		PlusControl = 3;
		if (GamePad.Up)
		{
			if (GamePad.Up)
			{
				u =0;
				v = 0;
				r = 0;
				process_SubState = 2;
				Manual = 0;
			}
		}
	}
	else if(process_SubState == 2){
		valve_ProcessBegin(ValveProcess_CatchAndHold);
		process_SubState = 3;

	}
	else if(process_SubState == 3){
		if(valve_IsProcessEnd()){
			process_SubState = 4;
		}
	}
	else if(process_SubState == 4){
		process_ResetFloatingEnc();
		Reset_MPU_Angle();
		process_SubState = 0;
		step += 1;
	}
}
void process_RiceAppRoach2()
{
	if(process_SubState == 0)
	{
		use_pidTheta = 1;
		if((process_ThucHienGapLua() == true) || GamePad.Down){
			process_Error(1);
			process_SubState = 1;
		}
	}
	else if(process_SubState == 1){
		process_Error(0);
		Manual = 1;
		PlusControl = 3;
		if (GamePad.Up)
		{
			if (GamePad.Up)
			{
				u =0;
				v = 0;
				r = 0;
				process_SubState = 2;
				Manual = 0;
			}
		}
	}
	else if(process_SubState == 2){
		valve_ProcessBegin(ValveProcess_CatchAndHold);
		process_SubState = 3;

	}
	else if(process_SubState == 3){
		if(valve_IsProcessEnd()){
			process_SubState = 4;
		}
	}
	else if(process_SubState == 4){
		process_ResetFloatingEnc();
		Reset_MPU_Angle();
		process_SubState = 0;
		step += 1;
	}
}
void process_RiceAppRoach3()
{
	if(process_SubState == 0)
	{
		use_pidTheta = 1;
		process_RunByAngle(180-16,0.15);
		if((process_ThucHienGapLua1() == true) || GamePad.Down){
			process_Error(1);

			process_SubState = 1;
			process_SSCheck = 0;
		}
	}
	else if(process_SubState == 1){
		process_Error(0);
		process_RunByAngle(90,0.2);

		Manual = 1;
		PlusControl = 3;
		if (GamePad.Up)
		{
			if (GamePad.Up)
			{
				process_SubState = 2;
				Manual = 0;
			}
		}
	}
	else if(process_SubState == 2){
		valve_ProcessBegin(ValveProcess_CatchAndHold);
		process_SubState = 3;

	}
	else if(process_SubState == 3){
		if(valve_IsProcessEnd()){
			process_SubState = 4;
		}
	}
	else if(process_SubState == 4){
		process_ResetFloatingEnc();
		Reset_MPU_Angle();
		process_SubState = 0;
		step += 1;
	}
}

uint16_t pwm1,pwm2,pwm3,pwm4;
/* USER CODE END 0 */

int main(void)
{

  /* MCU Configuration--------------------------------------------------------*/

  /* Reset of all peripherals, Initializes the Flash interface and the Systick. */
   HAL_Init();

  /* Configure the system clock */
  SystemClock_Config();

  /* Initialize all configured peripherals */
  MX_GPIO_Init();
  MX_DMA_Init();
  MX_CAN1_Init();
  MX_USART3_UART_Init();
  MX_TIM1_Init();
  MX_TIM10_Init();
  MX_USART1_UART_Init();
  MX_USART2_UART_Init();
  MX_TIM5_Init();
  MX_TIM9_Init();
  MX_TIM4_Init();
  MX_TIM3_Init();
  MX_TIM8_Init();
  /* USER CODE BEGIN 2 */

	HAL_UART_Receive_IT(&huart3, (uint8_t*) UARTRX3_Buffer, 9);
	HAL_UART_Receive_DMA(&huart1, (uint8_t*) mpu, 10);
	HAL_TIM_Encoder_Start(&htim1, TIM_CHANNEL_ALL);
	__HAL_DMA_DISABLE_IT(&hdma_usart1_rx, DMA_IT_HT);
	CAN_Init();
	valve_Init();
	process_Init();
	RB1_Gun_Init();
	RB1_CollectBallMotor_Init();

	RB1_SensorRegisterPin(Sensor7_GPIO_Port, Sensor7_Pin, RB1_SENSOR_ARM_LEFT);
	RB1_SensorRegisterPin(Sensor5_GPIO_Port, Sensor5_Pin, RB1_SENSOR_ARM_RIGHT);
	RB1_SensorRegisterPin(Sensor8_GPIO_Port, Sensor8_Pin, RB1_SENSOR_COLLECT_BALL_LEFT);
	RB1_SensorRegisterPin(Sensor4_GPIO_Port, Sensor4_Pin, RB1_SENSOR_COLLECT_BALL_RIGHT);
	MainF4Robot1App_Init();

	RB1_CollectBallMotor_On();
	__HAL_TIM_SET_COMPARE(&htim8,TIM_CHANNEL_3,24); // bắn 2
	__HAL_TIM_SET_COMPARE(&htim8, TIM_CHANNEL_4,24);// bắn 1
	HAL_Delay(1000);
	RB1_CollectBallMotor_Off();
	__HAL_TIM_SET_COMPARE(&htim8,TIM_CHANNEL_3,0);
	__HAL_TIM_SET_COMPARE(&htim8, TIM_CHANNEL_4,0);

  /* USER CODE END 2 */

  /* Create the thread(s) */
  /* definition and creation of defaultTask */
  osThreadDef(defaultTask, StartDefaultTask, osPriorityIdle, 0, 256);
  defaultTaskHandle = osThreadCreate(osThread(defaultTask), NULL);

  /* definition and creation of TaskInvKine */
  osThreadStaticDef(TaskInvKine, InverseKinematic, osPriorityNormal, 0, 256, TaskInvKineBuffer, &TaskInvKineControlBlock);
  TaskInvKineHandle = osThreadCreate(osThread(TaskInvKine), NULL);

  /* definition and creation of TaskCAN */
  osThreadStaticDef(TaskCAN, CAN_Bus, osPriorityAboveNormal, 0, 128, TaskCANBuffer, &TaskCANControlBlock);
  TaskCANHandle = osThreadCreate(osThread(TaskCAN), NULL);

  /* definition and creation of TaskActuator */
  osThreadDef(TaskActuator, Actuator, osPriorityAboveNormal, 0, 128);
  TaskActuatorHandle = osThreadCreate(osThread(TaskActuator), NULL);

  /* definition and creation of TaskOdometer */
  osThreadDef(TaskOdometer, OdometerHandle, osPriorityNormal, 0, 128);
  TaskOdometerHandle = osThreadCreate(osThread(TaskOdometer), NULL);

  /* definition and creation of TaskProcess */
  osThreadDef(TaskProcess, TaskRunProcess, osPriorityNormal, 0, 256);
  TaskProcessHandle = osThreadCreate(osThread(TaskProcess), NULL);

  /* Start scheduler */
  osKernelStart();

  /* We should never get here as control is now taken by the scheduler */
  /* Infinite loop */
	while (1) {

	}
}

void SystemClock_Config(void)
{
  RCC_OscInitTypeDef RCC_OscInitStruct = {0};
  RCC_ClkInitTypeDef RCC_ClkInitStruct = {0};

  /** Configure the main internal regulator output voltage
  */
  __HAL_RCC_PWR_CLK_ENABLE();
  __HAL_PWR_VOLTAGESCALING_CONFIG(PWR_REGULATOR_VOLTAGE_SCALE1);

  /** Initializes the RCC Oscillators according to the specified parameters
  * in the RCC_OscInitTypeDef structure.
  */
  RCC_OscInitStruct.OscillatorType = RCC_OSCILLATORTYPE_HSI;
  RCC_OscInitStruct.HSIState = RCC_HSI_ON;
  RCC_OscInitStruct.HSICalibrationValue = RCC_HSICALIBRATION_DEFAULT;
  RCC_OscInitStruct.PLL.PLLState = RCC_PLL_ON;
  RCC_OscInitStruct.PLL.PLLSource = RCC_PLLSOURCE_HSI;
  RCC_OscInitStruct.PLL.PLLM = 8;
  RCC_OscInitStruct.PLL.PLLN = 160;
  RCC_OscInitStruct.PLL.PLLP = RCC_PLLP_DIV2;
  RCC_OscInitStruct.PLL.PLLQ = 4;
  if (HAL_RCC_OscConfig(&RCC_OscInitStruct) != HAL_OK)
  {
    Error_Handler();
  }

  /** Initializes the CPU, AHB and APB buses clocks
  */
  RCC_ClkInitStruct.ClockType = RCC_CLOCKTYPE_HCLK|RCC_CLOCKTYPE_SYSCLK
                              |RCC_CLOCKTYPE_PCLK1|RCC_CLOCKTYPE_PCLK2;
  RCC_ClkInitStruct.SYSCLKSource = RCC_SYSCLKSOURCE_PLLCLK;
  RCC_ClkInitStruct.AHBCLKDivider = RCC_SYSCLK_DIV1;
  RCC_ClkInitStruct.APB1CLKDivider = RCC_HCLK_DIV4;
  RCC_ClkInitStruct.APB2CLKDivider = RCC_HCLK_DIV2;

  if (HAL_RCC_ClockConfig(&RCC_ClkInitStruct, FLASH_LATENCY_5) != HAL_OK)
  {
    Error_Handler();
  }
}

static void MX_CAN1_Init(void)
{

  hcan1.Instance = CAN1;
  hcan1.Init.Prescaler = 10;
  hcan1.Init.Mode = CAN_MODE_NORMAL;
  hcan1.Init.SyncJumpWidth = CAN_SJW_1TQ;
  hcan1.Init.TimeSeg1 = CAN_BS1_2TQ;
  hcan1.Init.TimeSeg2 = CAN_BS2_1TQ;
  hcan1.Init.TimeTriggeredMode = DISABLE;
  hcan1.Init.AutoBusOff = DISABLE;
  hcan1.Init.AutoWakeUp = DISABLE;
  hcan1.Init.AutoRetransmission = DISABLE;
  hcan1.Init.ReceiveFifoLocked = DISABLE;
  hcan1.Init.TransmitFifoPriority = DISABLE;
  if (HAL_CAN_Init(&hcan1) != HAL_OK)
  {
    Error_Handler();
  }

}

static void MX_TIM1_Init(void)
{

  TIM_Encoder_InitTypeDef sConfig = {0};
  TIM_MasterConfigTypeDef sMasterConfig = {0};

  htim1.Instance = TIM1;
  htim1.Init.Prescaler = 0;
  htim1.Init.CounterMode = TIM_COUNTERMODE_UP;
  htim1.Init.Period = 65535;
  htim1.Init.ClockDivision = TIM_CLOCKDIVISION_DIV1;
  htim1.Init.RepetitionCounter = 0;
  htim1.Init.AutoReloadPreload = TIM_AUTORELOAD_PRELOAD_DISABLE;
  sConfig.EncoderMode = TIM_ENCODERMODE_TI12;
  sConfig.IC1Polarity = TIM_ICPOLARITY_RISING;
  sConfig.IC1Selection = TIM_ICSELECTION_DIRECTTI;
  sConfig.IC1Prescaler = TIM_ICPSC_DIV1;
  sConfig.IC1Filter = 0;
  sConfig.IC2Polarity = TIM_ICPOLARITY_RISING;
  sConfig.IC2Selection = TIM_ICSELECTION_DIRECTTI;
  sConfig.IC2Prescaler = TIM_ICPSC_DIV1;
  sConfig.IC2Filter = 0;
  if (HAL_TIM_Encoder_Init(&htim1, &sConfig) != HAL_OK)
  {
    Error_Handler();
  }
  sMasterConfig.MasterOutputTrigger = TIM_TRGO_RESET;
  sMasterConfig.MasterSlaveMode = TIM_MASTERSLAVEMODE_DISABLE;
  if (HAL_TIMEx_MasterConfigSynchronization(&htim1, &sMasterConfig) != HAL_OK)
  {
    Error_Handler();
  }

}

static void MX_TIM3_Init(void)
{

  TIM_ClockConfigTypeDef sClockSourceConfig = {0};
  TIM_MasterConfigTypeDef sMasterConfig = {0};
  TIM_OC_InitTypeDef sConfigOC = {0};

  htim3.Instance = TIM3;
  htim3.Init.Prescaler = 80-1;
  htim3.Init.CounterMode = TIM_COUNTERMODE_UP;
  htim3.Init.Period = 1000-1;
  htim3.Init.ClockDivision = TIM_CLOCKDIVISION_DIV1;
  htim3.Init.AutoReloadPreload = TIM_AUTORELOAD_PRELOAD_DISABLE;
  if (HAL_TIM_Base_Init(&htim3) != HAL_OK)
  {
    Error_Handler();
  }
  sClockSourceConfig.ClockSource = TIM_CLOCKSOURCE_INTERNAL;
  if (HAL_TIM_ConfigClockSource(&htim3, &sClockSourceConfig) != HAL_OK)
  {
    Error_Handler();
  }
  if (HAL_TIM_PWM_Init(&htim3) != HAL_OK)
  {
    Error_Handler();
  }
  sMasterConfig.MasterOutputTrigger = TIM_TRGO_RESET;
  sMasterConfig.MasterSlaveMode = TIM_MASTERSLAVEMODE_DISABLE;
  if (HAL_TIMEx_MasterConfigSynchronization(&htim3, &sMasterConfig) != HAL_OK)
  {
    Error_Handler();
  }
  sConfigOC.OCMode = TIM_OCMODE_PWM1;
  sConfigOC.Pulse = 0;
  sConfigOC.OCPolarity = TIM_OCPOLARITY_HIGH;
  sConfigOC.OCFastMode = TIM_OCFAST_DISABLE;
  if (HAL_TIM_PWM_ConfigChannel(&htim3, &sConfigOC, TIM_CHANNEL_1) != HAL_OK)
  {
    Error_Handler();
  }
  if (HAL_TIM_PWM_ConfigChannel(&htim3, &sConfigOC, TIM_CHANNEL_2) != HAL_OK)
  {
    Error_Handler();
  }
  HAL_TIM_MspPostInit(&htim3);

}

static void MX_TIM4_Init(void)
{

  TIM_ClockConfigTypeDef sClockSourceConfig = {0};
  TIM_MasterConfigTypeDef sMasterConfig = {0};
  TIM_OC_InitTypeDef sConfigOC = {0};

  htim4.Instance = TIM4;
  htim4.Init.Prescaler = 80-1;
  htim4.Init.CounterMode = TIM_COUNTERMODE_UP;
  htim4.Init.Period = 1000-1;
  htim4.Init.ClockDivision = TIM_CLOCKDIVISION_DIV1;
  htim4.Init.AutoReloadPreload = TIM_AUTORELOAD_PRELOAD_DISABLE;
  if (HAL_TIM_Base_Init(&htim4) != HAL_OK)
  {
    Error_Handler();
  }
  sClockSourceConfig.ClockSource = TIM_CLOCKSOURCE_INTERNAL;
  if (HAL_TIM_ConfigClockSource(&htim4, &sClockSourceConfig) != HAL_OK)
  {
    Error_Handler();
  }
  if (HAL_TIM_PWM_Init(&htim4) != HAL_OK)
  {
    Error_Handler();
  }
  sMasterConfig.MasterOutputTrigger = TIM_TRGO_RESET;
  sMasterConfig.MasterSlaveMode = TIM_MASTERSLAVEMODE_DISABLE;
  if (HAL_TIMEx_MasterConfigSynchronization(&htim4, &sMasterConfig) != HAL_OK)
  {
    Error_Handler();
  }
  sConfigOC.OCMode = TIM_OCMODE_PWM1;
  sConfigOC.Pulse = 0;
  sConfigOC.OCPolarity = TIM_OCPOLARITY_HIGH;
  sConfigOC.OCFastMode = TIM_OCFAST_DISABLE;
  if (HAL_TIM_PWM_ConfigChannel(&htim4, &sConfigOC, TIM_CHANNEL_1) != HAL_OK)
  {
    Error_Handler();
  }
  if (HAL_TIM_PWM_ConfigChannel(&htim4, &sConfigOC, TIM_CHANNEL_2) != HAL_OK)
  {
    Error_Handler();
  }
  HAL_TIM_MspPostInit(&htim4);

}

static void MX_TIM5_Init(void)
{

  TIM_ClockConfigTypeDef sClockSourceConfig = {0};
  TIM_MasterConfigTypeDef sMasterConfig = {0};
  TIM_OC_InitTypeDef sConfigOC = {0};

  htim5.Instance = TIM5;
  htim5.Init.Prescaler = 80-1;
  htim5.Init.CounterMode = TIM_COUNTERMODE_UP;
  htim5.Init.Period = 1000-1;
  htim5.Init.ClockDivision = TIM_CLOCKDIVISION_DIV1;
  htim5.Init.AutoReloadPreload = TIM_AUTORELOAD_PRELOAD_DISABLE;
  if (HAL_TIM_Base_Init(&htim5) != HAL_OK)
  {
    Error_Handler();
  }
  sClockSourceConfig.ClockSource = TIM_CLOCKSOURCE_INTERNAL;
  if (HAL_TIM_ConfigClockSource(&htim5, &sClockSourceConfig) != HAL_OK)
  {
    Error_Handler();
  }
  if (HAL_TIM_PWM_Init(&htim5) != HAL_OK)
  {
    Error_Handler();
  }
  sMasterConfig.MasterOutputTrigger = TIM_TRGO_RESET;
  sMasterConfig.MasterSlaveMode = TIM_MASTERSLAVEMODE_DISABLE;
  if (HAL_TIMEx_MasterConfigSynchronization(&htim5, &sMasterConfig) != HAL_OK)
  {
    Error_Handler();
  }
  sConfigOC.OCMode = TIM_OCMODE_PWM1;
  sConfigOC.Pulse = 0;
  sConfigOC.OCPolarity = TIM_OCPOLARITY_HIGH;
  sConfigOC.OCFastMode = TIM_OCFAST_DISABLE;
  if (HAL_TIM_PWM_ConfigChannel(&htim5, &sConfigOC, TIM_CHANNEL_1) != HAL_OK)
  {
    Error_Handler();
  }
  if (HAL_TIM_PWM_ConfigChannel(&htim5, &sConfigOC, TIM_CHANNEL_2) != HAL_OK)
  {
    Error_Handler();
  }
  HAL_TIM_MspPostInit(&htim5);

}

static void MX_TIM8_Init(void)
{

  TIM_ClockConfigTypeDef sClockSourceConfig = {0};
  TIM_MasterConfigTypeDef sMasterConfig = {0};
  TIM_OC_InitTypeDef sConfigOC = {0};
  TIM_BreakDeadTimeConfigTypeDef sBreakDeadTimeConfig = {0};

  htim8.Instance = TIM8;
  htim8.Init.Prescaler = 75-1;
  htim8.Init.CounterMode = TIM_COUNTERMODE_UP;
  htim8.Init.Period = 255-1;
  htim8.Init.ClockDivision = TIM_CLOCKDIVISION_DIV1;
  htim8.Init.RepetitionCounter = 0;
  htim8.Init.AutoReloadPreload = TIM_AUTORELOAD_PRELOAD_DISABLE;
  if (HAL_TIM_Base_Init(&htim8) != HAL_OK)
  {
    Error_Handler();
  }
  sClockSourceConfig.ClockSource = TIM_CLOCKSOURCE_INTERNAL;
  if (HAL_TIM_ConfigClockSource(&htim8, &sClockSourceConfig) != HAL_OK)
  {
    Error_Handler();
  }
  if (HAL_TIM_PWM_Init(&htim8) != HAL_OK)
  {
    Error_Handler();
  }
  sMasterConfig.MasterOutputTrigger = TIM_TRGO_RESET;
  sMasterConfig.MasterSlaveMode = TIM_MASTERSLAVEMODE_DISABLE;
  if (HAL_TIMEx_MasterConfigSynchronization(&htim8, &sMasterConfig) != HAL_OK)
  {
    Error_Handler();
  }
  sConfigOC.OCMode = TIM_OCMODE_PWM1;
  sConfigOC.Pulse = 0;
  sConfigOC.OCPolarity = TIM_OCPOLARITY_HIGH;
  sConfigOC.OCNPolarity = TIM_OCNPOLARITY_HIGH;
  sConfigOC.OCFastMode = TIM_OCFAST_DISABLE;
  sConfigOC.OCIdleState = TIM_OCIDLESTATE_RESET;
  sConfigOC.OCNIdleState = TIM_OCNIDLESTATE_RESET;
  if (HAL_TIM_PWM_ConfigChannel(&htim8, &sConfigOC, TIM_CHANNEL_3) != HAL_OK)
  {
    Error_Handler();
  }
  if (HAL_TIM_PWM_ConfigChannel(&htim8, &sConfigOC, TIM_CHANNEL_4) != HAL_OK)
  {
    Error_Handler();
  }
  sBreakDeadTimeConfig.OffStateRunMode = TIM_OSSR_DISABLE;
  sBreakDeadTimeConfig.OffStateIDLEMode = TIM_OSSI_DISABLE;
  sBreakDeadTimeConfig.LockLevel = TIM_LOCKLEVEL_OFF;
  sBreakDeadTimeConfig.DeadTime = 0;
  sBreakDeadTimeConfig.BreakState = TIM_BREAK_DISABLE;
  sBreakDeadTimeConfig.BreakPolarity = TIM_BREAKPOLARITY_HIGH;
  sBreakDeadTimeConfig.AutomaticOutput = TIM_AUTOMATICOUTPUT_DISABLE;
  if (HAL_TIMEx_ConfigBreakDeadTime(&htim8, &sBreakDeadTimeConfig) != HAL_OK)
  {
    Error_Handler();
  }
  HAL_TIM_MspPostInit(&htim8);

}

static void MX_TIM9_Init(void)
{

  TIM_ClockConfigTypeDef sClockSourceConfig = {0};

  htim9.Instance = TIM9;
  htim9.Init.Prescaler = 75-1;
  htim9.Init.CounterMode = TIM_COUNTERMODE_UP;
  htim9.Init.Period = 255-1;
  htim9.Init.ClockDivision = TIM_CLOCKDIVISION_DIV1;
  htim9.Init.AutoReloadPreload = TIM_AUTORELOAD_PRELOAD_DISABLE;
  if (HAL_TIM_Base_Init(&htim9) != HAL_OK)
  {
    Error_Handler();
  }
  sClockSourceConfig.ClockSource = TIM_CLOCKSOURCE_INTERNAL;
  if (HAL_TIM_ConfigClockSource(&htim9, &sClockSourceConfig) != HAL_OK)
  {
    Error_Handler();
  }

}

static void MX_TIM10_Init(void)
{

  htim10.Instance = TIM10;
  htim10.Init.Prescaler = 160-1;
  htim10.Init.CounterMode = TIM_COUNTERMODE_UP;
  htim10.Init.Period = 65000;
  htim10.Init.ClockDivision = TIM_CLOCKDIVISION_DIV1;
  htim10.Init.AutoReloadPreload = TIM_AUTORELOAD_PRELOAD_DISABLE;
  if (HAL_TIM_Base_Init(&htim10) != HAL_OK)
  {
    Error_Handler();
  }

}

static void MX_USART1_UART_Init(void)
{

  huart1.Instance = USART1;
  huart1.Init.BaudRate = 115200;
  huart1.Init.WordLength = UART_WORDLENGTH_8B;
  huart1.Init.StopBits = UART_STOPBITS_1;
  huart1.Init.Parity = UART_PARITY_NONE;
  huart1.Init.Mode = UART_MODE_TX_RX;
  huart1.Init.HwFlowCtl = UART_HWCONTROL_NONE;
  huart1.Init.OverSampling = UART_OVERSAMPLING_16;
  if (HAL_UART_Init(&huart1) != HAL_OK)
  {
    Error_Handler();
  }

}

static void MX_USART2_UART_Init(void)
{

  huart2.Instance = USART2;
  huart2.Init.BaudRate = 115200;
  huart2.Init.WordLength = UART_WORDLENGTH_8B;
  huart2.Init.StopBits = UART_STOPBITS_1;
  huart2.Init.Parity = UART_PARITY_NONE;
  huart2.Init.Mode = UART_MODE_TX_RX;
  huart2.Init.HwFlowCtl = UART_HWCONTROL_NONE;
  huart2.Init.OverSampling = UART_OVERSAMPLING_16;
  if (HAL_UART_Init(&huart2) != HAL_OK)
  {
    Error_Handler();
  }

}

static void MX_USART3_UART_Init(void)
{

  huart3.Instance = USART3;
  huart3.Init.BaudRate = 115200;
  huart3.Init.WordLength = UART_WORDLENGTH_8B;
  huart3.Init.StopBits = UART_STOPBITS_1;
  huart3.Init.Parity = UART_PARITY_NONE;
  huart3.Init.Mode = UART_MODE_TX_RX;
  huart3.Init.HwFlowCtl = UART_HWCONTROL_NONE;
  huart3.Init.OverSampling = UART_OVERSAMPLING_16;
  if (HAL_UART_Init(&huart3) != HAL_OK)
  {
    Error_Handler();
  }

}

static void MX_DMA_Init(void)
{

  /* DMA controller clock enable */
  __HAL_RCC_DMA2_CLK_ENABLE();

  /* DMA interrupt init */
  /* DMA2_Stream2_IRQn interrupt configuration */
  HAL_NVIC_SetPriority(DMA2_Stream2_IRQn, 5, 0);
  HAL_NVIC_EnableIRQ(DMA2_Stream2_IRQn);

}

static void MX_GPIO_Init(void)
{
  GPIO_InitTypeDef GPIO_InitStruct = {0};

  /* GPIO Ports Clock Enable */
  __HAL_RCC_GPIOE_CLK_ENABLE();
  __HAL_RCC_GPIOC_CLK_ENABLE();
  __HAL_RCC_GPIOA_CLK_ENABLE();
  __HAL_RCC_GPIOB_CLK_ENABLE();
  __HAL_RCC_GPIOD_CLK_ENABLE();

  /*Configure GPIO pin Output Level */
  HAL_GPIO_WritePin(GPIOE, Buzzer_Pin|RelayCollectBallLeft_Pin|RelayCollectBallRight_Pin, GPIO_PIN_RESET);

  /*Configure GPIO pin Output Level */
  HAL_GPIO_WritePin(GPIOC, Status_Pin|RobotSignalBtn_VCC_Pin|RobotSignalBtn_GND_Pin, GPIO_PIN_RESET);

  /*Configure GPIO pin Output Level */
  HAL_GPIO_WritePin(GPIOA, HC595_CLK_Pin|HC595_RCLK_Pin|HC595_OE_Pin|HC595_DATA_Pin, GPIO_PIN_RESET);

  /*Configure GPIO pin Output Level */
  HAL_GPIO_WritePin(RelayRulo_GPIO_Port, RelayRulo_Pin, GPIO_PIN_RESET);

  /*Configure GPIO pins : Buzzer_Pin RelayCollectBallLeft_Pin RelayCollectBallRight_Pin */
  GPIO_InitStruct.Pin = Buzzer_Pin|RelayCollectBallLeft_Pin|RelayCollectBallRight_Pin;
  GPIO_InitStruct.Mode = GPIO_MODE_OUTPUT_PP;
  GPIO_InitStruct.Pull = GPIO_NOPULL;
  GPIO_InitStruct.Speed = GPIO_SPEED_FREQ_LOW;
  HAL_GPIO_Init(GPIOE, &GPIO_InitStruct);

  /*Configure GPIO pins : Status_Pin RobotSignalBtn_VCC_Pin RobotSignalBtn_GND_Pin */
  GPIO_InitStruct.Pin = Status_Pin|RobotSignalBtn_VCC_Pin|RobotSignalBtn_GND_Pin;
  GPIO_InitStruct.Mode = GPIO_MODE_OUTPUT_PP;
  GPIO_InitStruct.Pull = GPIO_NOPULL;
  GPIO_InitStruct.Speed = GPIO_SPEED_FREQ_LOW;
  HAL_GPIO_Init(GPIOC, &GPIO_InitStruct);

  /*Configure GPIO pins : HC595_CLK_Pin HC595_RCLK_Pin HC595_OE_Pin HC595_DATA_Pin */
  GPIO_InitStruct.Pin = HC595_CLK_Pin|HC595_RCLK_Pin|HC595_OE_Pin|HC595_DATA_Pin;
  GPIO_InitStruct.Mode = GPIO_MODE_OUTPUT_PP;
  GPIO_InitStruct.Pull = GPIO_NOPULL;
  GPIO_InitStruct.Speed = GPIO_SPEED_FREQ_LOW;
  HAL_GPIO_Init(GPIOA, &GPIO_InitStruct);

  /*Configure GPIO pins : Sensor1_Pin Sensor2_Pin Sensor4_Pin Sensor5_Pin
                           Sensor6_Pin Sensor7_Pin Sensor8_Pin */
  GPIO_InitStruct.Pin = Sensor1_Pin|Sensor2_Pin|Sensor4_Pin|Sensor5_Pin
                          |Sensor6_Pin|Sensor7_Pin|Sensor8_Pin;
  GPIO_InitStruct.Mode = GPIO_MODE_IT_RISING;
  GPIO_InitStruct.Pull = GPIO_NOPULL;
  HAL_GPIO_Init(GPIOE, &GPIO_InitStruct);

  /*Configure GPIO pins : RobotSignalBtn_RED_Pin RobotSignalBtn_YELLOW_Pin RobotSignalBtn_BLUE_Pin RobotSignalBtn_GREEN_Pin */
  GPIO_InitStruct.Pin = RobotSignalBtn_RED_Pin|RobotSignalBtn_YELLOW_Pin|RobotSignalBtn_BLUE_Pin|RobotSignalBtn_GREEN_Pin;
  GPIO_InitStruct.Mode = GPIO_MODE_INPUT;
  GPIO_InitStruct.Pull = GPIO_NOPULL;
  HAL_GPIO_Init(GPIOD, &GPIO_InitStruct);

  /*Configure GPIO pin : Enc2B_Pin */
  GPIO_InitStruct.Pin = Enc2B_Pin;
  GPIO_InitStruct.Mode = GPIO_MODE_INPUT;
  GPIO_InitStruct.Pull = GPIO_PULLUP;
  HAL_GPIO_Init(Enc2B_GPIO_Port, &GPIO_InitStruct);

  /*Configure GPIO pin : Enc2A_Pin */
  GPIO_InitStruct.Pin = Enc2A_Pin;
  GPIO_InitStruct.Mode = GPIO_MODE_IT_RISING;
  GPIO_InitStruct.Pull = GPIO_PULLUP;
  HAL_GPIO_Init(Enc2A_GPIO_Port, &GPIO_InitStruct);

  /*Configure GPIO pin : Enc1B_Pin */
  GPIO_InitStruct.Pin = Enc1B_Pin;
  GPIO_InitStruct.Mode = GPIO_MODE_INPUT;
  GPIO_InitStruct.Pull = GPIO_PULLUP;
  HAL_GPIO_Init(Enc1B_GPIO_Port, &GPIO_InitStruct);

  /*Configure GPIO pin : Enc1A_Pin */
  GPIO_InitStruct.Pin = Enc1A_Pin;
  GPIO_InitStruct.Mode = GPIO_MODE_IT_RISING;
  GPIO_InitStruct.Pull = GPIO_PULLUP;
  HAL_GPIO_Init(Enc1A_GPIO_Port, &GPIO_InitStruct);

  /*Configure GPIO pin : RelayRulo_Pin */
  GPIO_InitStruct.Pin = RelayRulo_Pin;
  GPIO_InitStruct.Mode = GPIO_MODE_OUTPUT_PP;
  GPIO_InitStruct.Pull = GPIO_NOPULL;
  GPIO_InitStruct.Speed = GPIO_SPEED_FREQ_LOW;
  HAL_GPIO_Init(RelayRulo_GPIO_Port, &GPIO_InitStruct);

  /* EXTI interrupt init*/
  HAL_NVIC_SetPriority(EXTI3_IRQn, 5, 0);
  HAL_NVIC_EnableIRQ(EXTI3_IRQn);

  HAL_NVIC_SetPriority(EXTI9_5_IRQn, 5, 0);
  HAL_NVIC_EnableIRQ(EXTI9_5_IRQn);

  HAL_NVIC_SetPriority(EXTI15_10_IRQn, 5, 0);
  HAL_NVIC_EnableIRQ(EXTI15_10_IRQn);

}

/* USER CODE BEGIN 4 */

void InvCpltCallback(ModuleID ID, float speed, float angle) {
	CAN_SpeedBLDC_AngleDC speedAngle;
	speedAngle.bldcSpeed = speed;
	speedAngle.dcAngle = angle;
	canfunc_MotorPutSpeedAndAngle(speedAngle);
	while (canctrl_Send(&hcan1, ID) != HAL_OK)
		;
}
/* USER CODE END 4 */

void StartDefaultTask(void const * argument)
{
  /* USER CODE BEGIN 5 */
	swer_Init();
	/* Infinite loop */
	for (;;) {
		if(Retry == 1 && GamePad.Touch == 1){
			osDelay(1000);
			if(GamePad.Touch == 1){
				ShootBallTime_Start(&GamePad);
			}
		}
		osDelay(50);
	}
  /* USER CODE END 5 */
}

/* USER CODE BEGIN Header_InverseKinematic */

void process_WireRelease(bool isUntangleWire){
	for(CAN_DEVICE_ID id = CANCTRL_DEVICE_MOTOR_CONTROLLER_1; id <=CANCTRL_DEVICE_MOTOR_CONTROLLER_3;id++){
		canfunc_SetBoolValue(isUntangleWire,CANCTRL_MODE_UNTANGLE_WIRE);
		while(canctrl_Send(&hcan1, id) != HAL_OK);
	}
}

/**
 * @brief Function implementing the TaskInvKine thread.
 * @param argument: Not used
 * @retval None
 */

/* USER CODE END Header_InverseKinematic */
void InverseKinematic(void const * argument)
{
  /* USER CODE BEGIN InverseKinematic */
	/* Infinite loop */
	for (;;) {
		if(nodeSwerveSetHomeComplete == 14){
			if (xaDay == 0 && safetyMode == 0)
					{
				invkine_Implementation(MODULE_ID_3, uControlX, uControlY, uControlTheta, &InvCpltCallback);
				invkine_Implementation(MODULE_ID_1, uControlX, uControlY, uControlTheta, &InvCpltCallback);
				invkine_Implementation(MODULE_ID_2, uControlX, uControlY, uControlTheta, &InvCpltCallback);
			}
			else if (xaDay == 1)
			{
				process_WireRelease(1);
			}
			else if(xaDay == 2)
			{
				process_WireRelease(0);
				xaDay = 0;
			}
			else if(safetyMode == 1)
			{
				invkine_Implementation(MODULE_ID_3, 0, 0, 0, &InvCpltCallback);
				invkine_Implementation(MODULE_ID_1, 0, 0, 0, &InvCpltCallback);
				invkine_Implementation(MODULE_ID_2, 0, 0, 0, &InvCpltCallback);
			}
		}
		if (gamepadRxIsBusy) {
			gamepadRxIsBusy = 0;
			HAL_UART_Receive_IT(&huart3, (uint8_t*) UARTRX3_Buffer, 9);
		}
		if ((huart3.Instance->CR1 & USART_CR1_UE) == 0) {
			__HAL_UART_ENABLE(&huart3);
		}
		osDelay(50);
	}
  /* USER CODE END InverseKinematic */
}

/* USER CODE BEGIN Header_CAN_Bus */
/**
 * @brief Function implementing the TaskCAN thread.
 * @param argument: Not used
 * @retval None
 *
 */
/* USER CODE END Header_CAN_Bus */
void CAN_Bus(void const * argument)
{
  /* USER CODE BEGIN CAN_Bus */
	CAN_Init();
	osDelay(1000);
	canctrl_RTR_TxRequest(&hcan1, CANCTRL_DEVICE_MOTOR_CONTROLLER_1,
			CANCTRL_MODE_SET_HOME);
	osDelay(10);
	canctrl_RTR_TxRequest(&hcan1, CANCTRL_DEVICE_MOTOR_CONTROLLER_2,
			CANCTRL_MODE_SET_HOME);
	osDelay(10);
	canctrl_RTR_TxRequest(&hcan1, CANCTRL_DEVICE_MOTOR_CONTROLLER_3,
			CANCTRL_MODE_SET_HOME);
	osDelay(10);
	uint32_t modeID;
	/* Infinite loop */
	for (;;) {
		if (xTaskNotifyWait(pdFALSE, pdFALSE, &modeID, portMAX_DELAY)) {
			CAN_RxHeaderTypeDef rxHeader = canctrl_GetRxHeader();
			uint32_t targetID = rxHeader.StdId >> CAN_DEVICE_POS;
			if ((modeID == CANCTRL_MODE_SET_HOME
					|| modeID == CANCTRL_MODE_ROBOT_ERROR)
					&& targetID) {
				handleFunctionCAN(modeID, targetID);
			}
			HAL_CAN_ActivateNotification(&hcan1, CAN_IT_RX_FIFO0_MSG_PENDING);
		}
	}
  /* USER CODE END CAN_Bus */
}

/* USER CODE BEGIN Header_Actuator */

void SignalButton_Pressed(SignalButtonColor color){

	switch(color){
	case SIGBTN_RED:
		Red = 1;
		Reset_MPU_Angle();
		process_ResetFloatingEnc();
		break;
	case SIGBTN_YELLOW:
		Retry = 1;
		Reset_MPU_Angle();
		process_ResetFloatingEnc();
		break;
	case SIGBTN_BLUE:
		Blue = 1;
		Reset_MPU_Angle();
		process_ResetFloatingEnc();
		break;
	case SIGBTN_GREEN:
		step = 1;
		Run = 1;
		Reset_MPU_Angle();
		process_ResetFloatingEnc();
		break;
	default:
		break;
	}

}
/**
 * @brief Function implementing the TaskActuator thread.
 * @param argument: Not used
 * @retval None
 */
/* USER CODE END Header_Actuator */
void Actuator(void const * argument)
{
  /* USER CODE BEGIN Actuator */
	RobotSignalButton_RegisterButtonPressedCallback(&SignalButton_Pressed);
	/* Infinite loop */
	for (;;) {
		RB1_CollectBallMotor_ControlSpeed();
		RB1_SensorTriggerHandle();
		RB1_CalculateRuloGunPIDSpeed();
		RB1_valve_ProcessManager();
		ShootBallTime_Handle();
		BuzzerBeepProcess();
		if(Run == 0)
		{
			RobotSignalButton_ScanButton();
		}
		osDelay(10);
	}
  /* USER CODE END Actuator */
}

void OdometerHandle(void const * argument)
{
  /* USER CODE BEGIN OdometerHandle */

	/* Infinite loop */
	osDelay(1000);

//			process_ReadVel_Init();
	/* Infinite loop */
	for (;;) {
//				ss = HAL_GPIO_ReadPin(sensor_5_GPIO_Port, sensor_5_Pin);
//				encPutBall = encoder_GetPulse(&PutBall_Enc, MODE_X4);
//	///////////////////////////////////////////////////////////////////////////////////////////////////////
//	/*---------------------------------------------------------------------------------------------------
//				if(step == 0)// Buoc khoi dong sethome
//				{// Reset co cau ve mac dinh
//					// if (dieu kien sethome da xong)step = 1;
//				}
//				else if(step == 2)//	Doi nhan nut de chay
//				{
//					// if (dieu kien nut nhan duoc nhan)step = 2;
//				}
//				else if(step == 3)//	Robot chay toi khu vuc lay banh
//				{
//					// if (s chua toi hoac s nho hon quang duong)process_Accel_FloatingEnc(Angle,maxSpeed,s,accel);
//					// if (da toi) DungRobot(); Step = 4;
//				}
//				else if(step == 4)// Doi Nhan nut de chay tiep
//				{
//					// if (dieu kien nut nhan duoc nhan)step = 5;
//				}
//	--------------------------------------------CODE MAU--------------------------------------------------*/
//
		trajecTheta.t += DELTA_T;
		Get_MPU_Angle();
		angle_Rad = (a_Now / 10.0) * M_PI / 180.0;
		process_SetFloatingEnc();
		trajecPlan_Cal(&trajecTheta);
		process_PD_Auto_Chose(trajecTheta.xdottraject, angle_Rad);
		if (use_pidTheta)
		{
			r = -(PID_Calculate(&pid_Angle, (float) trajecTheta.xTrajec, (float) angle_Rad) + (float) trajecTheta.xdottraject);

		}
//
//				process_Error(check);
//	///////////////////////////////////////////////////CODE O DAY/////////////////////////////////////////////////////

	if(Retry == 1)
	{
		Manual = 1;
		PlusControl = 4;
	}
	if(Red == 1)
	{
		if (step == 0)
				{	//Ra lenh cho co Cau lay bong di len cham chu U
			process_RunByAngle(-45,0.001);
			if (GamePad.Up)
			{
				osDelay(500);
				if (GamePad.Up)
				{	//Reset thong so enc tha troi va la ban :
					Reset_MPU_Angle();
					process_ResetFloatingEnc();
					// Set thong so quy hoach quy dao :
					step = 1;
				}
			}
		}

		// Cap lua thu 1
		else if (step == 1)
		{

			AngleNow = -45;
			process_Accel_FloatingEnc6(-45, 1, 1800, 0.5, 0, 3, 5);
			if(floatingEncCount > 1500)
			{
				step++;

			}
		}
		else if (step == 2)
		{
			AngleNow = 12;

			process_Accel_FloatingEnc9(12, 1.3, 18000, 0.5, 0, 3, 5);
			if(floatingEncCount > 3000)
			{
				process_SubState = 0;
				step++;

				V_want=1.2;
			}
		}
		else if (step == 3)
		{

			AngleNow = 5;
			if((floatingEncCount > 4000)&&(V_want>0.2))
			{
				V_want-=0.01;

			}
			process_Accel_FloatingEnc9(5, V_want, 18000, 0.5, 0, 3, 5);
			if(floatingEncCount > 9200)
			{
				process_SubState = 0;
				step++;

			}
				}
		else if(step == 4)
		{
			AngleNow = 15;
			process_Accel_FloatingEnc9(15, 0.2, 100000, 0.08, 0, 3, 5);
			if((floatingEncCount>1700)&&(floatingEncCount<3000))
			{
				if(process_ThucHienGapLua1() == true)
				{
					osDelay(1);
					if(process_ThucHienGapLua1() == true)
					{
						u = 0;
						v = 0;
						r= 0;
						use_pidTheta = 0;
						BuzzerBeep_Start(2, 50, 50);
						step = 5;
					}
				}
			}

			if((floatingEncCount>3000)|| GamePad.Down)//3000
			{
				u = 0;
				v = 0;
				r= 0;
				use_pidTheta = 0;
		    	step = 5;
			}
		}
		else if(step == 5)
		{
			process_RunByAngle(90, 0.2);
			process_SSCheck++;
			if(process_SSCheck>10)
			{
				step++;
				process_SSCheck = 0;
			}
		}
		else if(step == 6)
		{
			u = 0;
//			v = 0;
			r= 0;
//			use_pidTheta = 0;
			process_RiceAppRoach();
		}
		else if(step == 7)
		{
			AngleNow = -90;
			process_Accel_FloatingEnc6(-90, 0.6, 10000, 1.2, 0, 3,5);
			if(floatingEncCount>300){
				process_SubState = 0;
				step+=1;
			}
		}
		else if(step == 8)
		{
			process_Accel_FloatingEnc6(-180, 1, 13000, 0.5, 95, 1.5, 5);
			if(floatingEncCount> 1500)
			{
				process_SubState = 0;
				step++;
			}
		}
		else if(step == 9)
		{

			process_Accel_FloatingEnc9(-90, 0.8, 10000, 1, 95, 1.5, 5);
			if(floatingEncCount>6600)
			{
				valve_ArmDown();
				step++;
			}
		}
		else if(step == 10)
		{
			process_Accel_FloatingEnc9(-90, 0, 0, 1, 95, 1, 5);
		}
		else if (step == 11)
		{
			Manual = 1;
			PlusControl = 2;
			if (GamePad.Up)
			{
				osDelay(200);
				if (GamePad.Up)
				{
					process_ResetFloatingEnc();
					// Set thong so quy hoach quy dao :
					PlusControl = 0;
					Manual = 0;
					// tha tay gap
					process_Error(1);
					valve_HandRelease();
					process_Error(0);
					osDelay(50);
					valve_ArmUp();
					osDelay(250);
					step ++;
					process_Count++;
				}
			}
		}

	 //Cap lua thu 2 4 6
		else if(step == 12)
		{
			AngleNow = 180;
			process_Accel_FloatingEnc6(180, 0.6, 500, 0.08, 95, 3, 5);
		}
		else if(step == 13)
		{
			process_Accel_FloatingEnc6(70, 1, 15000, 0.5, -5, 1.5, 5);
			if(floatingEncCount>9400)
			{
				process_SubState = 0;
				step++;
			}
		}
		else if(step == 14)
		{
			process_Accel_FloatingEnc6(15, 0.4, 100000, 0.08, 0, 3, 5);
			if((floatingEncCount>4000)&&(floatingEncCount<5500))
			{
				if(process_ThucHienGapLua1() == true)
				{
					osDelay(1);
					if(process_ThucHienGapLua1() == true)
					{

						u = 0;
						v = 0;
						r= 0;
						use_pidTheta = 0;
						BuzzerBeep_Start(2, 50, 50);
						step = 15;

					}
				}
			}

			if(floatingEncCount>5500|| GamePad.Down)//3000
			{
				u = 0;
				v = 0;
				r= 0;
				use_pidTheta = 0;
		    	step = 15;
			}
		}
		else if(step == 15)
		{
			process_RunByAngle(90, 0.2);
			process_SSCheck++;
			if(process_SSCheck>10)
			{
				step++;
				process_SSCheck = 0;
			}
		}
		else if(step == 16)
		{
			u = 0;
			r= 0;
			process_RiceAppRoach();
		}
		else if(step == 17)
		{
			AngleNow = -90;
			process_Accel_FloatingEnc6(-90, 0.6, 10000, 1.2, 0, 3,5);
			if(floatingEncCount>300){
				process_SubState = 0;
				step+=1;
			}
		}
		else if(step == 18)
		{
			process_Accel_FloatingEnc6(-180, 1, 130000, 0.5, 95, 1.5, 5);

			if(floatingEncCount> 2600)
			{
				process_SubState = 0;
				step++;
			}
		}
		else if(step == 19)
		{
			process_Accel_FloatingEnc9(-90, 0.8, 10000, 1, 95, 1.5, 5);
			if(floatingEncCount>5800)
			{
				valve_ArmDown();
				step++;
			}
		}
		else if(step == 20)
		{
			process_Accel_FloatingEnc9(-90, 0, 0, 1, 95, 1, 5);
		}
		else if (step == 21)
		{
			Manual = 1;
			PlusControl = 2;
			if (GamePad.Up)
			{
				osDelay(200);
				if (GamePad.Up)
				{
					process_ResetFloatingEnc();
					// Set thong so quy hoach quy dao :
					PlusControl = 0;
					Manual = 0;
					// tha tay gap
					process_Error(1);
					valve_HandRelease();
					process_Error(0);
					osDelay(50);
					valve_ArmUp();
					osDelay(250);

					process_Count++;

					if(process_Count == 6)
					{
						step = 32;
					}
					else
					{
						step = 22;
					}

				}
			}
		}

		// Cap lua thu 3
		else if(step == 22)
		{
			AngleNow = 180;
			process_Accel_FloatingEnc6(180, 0.6, 1000, 0.08, 95, 3, 5);
		}
		else if(step == 23)
		{
			process_Accel_FloatingEnc6(75, 1, 15000, 0.5, -5, 1.5, 5);
			if(floatingEncCount>10000)
			{
				process_SubState = 0;
				step++;
			}
		}
		else if(step == 24)
		{
			process_Accel_FloatingEnc6(15, 0.4, 100000, 0.08, 0, 3, 5);
			if((floatingEncCount>4000)&&(floatingEncCount<5000))
			{
				if(process_ThucHienGapLua1() == true)
				{
					osDelay(1);
					if(process_ThucHienGapLua1() == true)
					{

						u = 0;
						v = 0;
						r= 0;
						use_pidTheta = 0;
						BuzzerBeep_Start(2, 50, 50);
						step = 25;

					}
				}
			}

			if(floatingEncCount>5000|| GamePad.Down)//3000
			{
				u = 0;
				v = 0;
				r= 0;
				use_pidTheta = 0;
		    	step = 25;
			}
		}
		else if(step == 25)
		{
			process_RunByAngle(90, 0.2);
			process_SSCheck++;
			if(process_SSCheck>10)
			{
				step++;
				process_SSCheck = 0;
			}
		}
		else if(step == 26)
		{
			u = 0;
//			v = 0;
			r= 0;
			process_RiceAppRoach();
		}
		else if(step == 27)
		{
			AngleNow = -90;
			process_Accel_FloatingEnc6(-90, 0.6, 10000, 1.2, 0, 3,5);
			if(floatingEncCount>300){
				process_SubState = 0;
				step+=1;
			}
		}
		else if(step == 28)
		{

			process_Accel_FloatingEnc6(-180, 1, 13000, 1, 95, 1.5, 5);
			if(floatingEncCount> 1400)
			{
				process_SubState = 0;
				step++;
			}
		}
		else if(step == 29)
		{

			process_Accel_FloatingEnc9(-90, 0.8, 10000, 1, 95, 1.5, 5);
			if(floatingEncCount>6400)
			{
				valve_ArmDown();
				step++;
			}

		}
		else if(step == 30)
		{
			process_Accel_FloatingEnc9(-90, 0, 0, 0.5, 95, 1, 5);

		}
		else if (step == 31)
		{
			Manual = 1;
			PlusControl = 2;
			if (GamePad.Up)
			{
				osDelay(200);
				if (GamePad.Up)
				{
					process_ResetFloatingEnc();
					// Set thong so quy hoach quy dao :
					PlusControl = 0;
					Manual = 0;
					// tha tay gap
					process_Error(1);
					valve_HandRelease();
					process_Error(0);
					osDelay(50);
					valve_ArmUp();
					osDelay(250);
					step = 12;
					process_Count++;
				}
			}
			// NUT LAY 6 LUA
//			if (GamePad.Left)
//			{
//				osDelay(200);
//				if(GamePad.Left)
//				{
//					process_ResetFloatingEnc();
//					// Set thong so quy hoach quy dao :
//					PlusControl = 0;
//					Manual = 0;
//					// tha tay gap
//					process_Error(1);
//					valve_HandRelease();
//					process_Error(0);
//					osDelay(50);
//					valve_ArmUp();
//					osDelay(250);
//					process_Count++;
//					if(process_Count == 3)
//					{
//						step = 32;
//					}
//
//				}
//			}

		}

		// Chay len khu 2
		else if(step == 32)
		{
			AngleNow = -180;
			if(process_Count == 6)
			{

				process_Accel_FloatingEnc6(-180, 1, 2200, 0.08, 95, 3, 5);
			}
			if(process_Count == 3)
			{

				process_Accel_FloatingEnc6(-180, 1, 10800, 0.08, 95, 3, 5);
			}
		}
		else if(step == 33)
		{
			process_Accel_FloatingEnc6(-88, 1, 13100, 0.5 , 95, 3, 5);
		}
		else if(step == 34)
		{
			process_Accel_FloatingEnc6(0, 1, 5800, 0.5, 95, 3, 5);
		}
		else if(step == 35){
			ShootBallTime_Start(&GamePad);
			step++;
		}
		else if(step == 36){
			Manual = 1;
			PlusControl = 2;
			if(IsInShootBallTime() == false){
				PlusControl = 0;
				step += 1;
			}
		}
	}

	/////////////////////////////////// SAN XANH///////////////////////////////////////////////
	if(Blue == 1)
	{
		if (step == 0)
				{	//Ra lenh cho co Cau lay bong di len cham chu U
			process_RunByAngle(-135,0.001);
			if (GamePad.Up)
			{
				osDelay(500);
				if (GamePad.Up)
				{	//Reset thong so enc tha troi va la ban :
					Reset_MPU_Angle();
					process_ResetFloatingEnc();
					// Set thong so quy hoach quy dao :
					step = 1;
				}
			}
		}

		// Cap lua thu 1
		else if (step == 1)
		{
			AngleNow = -135;
			process_Accel_FloatingEnc6(-135, 1, 1800, 0.5, 0, 3, 5);
			if(floatingEncCount > 1500)
			{
				step++;

			}
		}
		else if (step == 2)
		{
			AngleNow = 180-12;

			process_Accel_FloatingEnc9(180-12, 1.3, 18000, 0.5, 0, 3, 5);
			if(floatingEncCount > 3000)
			{
				process_SubState = 0;
				step++;

				V_want=1.2;
			}
		}
		else if (step == 3)
		{

			AngleNow = 180-5;
			if((floatingEncCount > 4000)&&(V_want>0.2))
			{
				V_want-=0.01;

			}
			process_Accel_FloatingEnc9(180-5, V_want, 18000, 0.5, 0, 3, 5);
			if(floatingEncCount > 9200)
			{
				process_SubState = 0;
				step++;

			}
				}
		else if(step == 4)
		{
			AngleNow = 180-20;
			process_Accel_FloatingEnc9(180-18, 0.2, 100000, 0.08, 0, 3, 5);
			if((floatingEncCount>1500)&&(floatingEncCount<2500))
			{
				if(process_ThucHienGapLua() == true)
				{
					osDelay(1);
					if(process_ThucHienGapLua() == true)
					{
						u = 0;
						v = 0;
						r= 0;
						use_pidTheta = 0;
						BuzzerBeep_Start(2, 50, 50);
						step = 5;
					}
				}
			}

			if((floatingEncCount>2500) || GamePad.Down)//3000
			{
				u = 0;
				v = 0;
				r= 0;
				use_pidTheta = 0;
		    	step = 5;
			}
		}
		else if(step == 5)
		{
			process_RunByAngle(90, 0.2);
			process_SSCheck++;
			if(process_SSCheck>10)
			{
				step++;
				process_SSCheck = 0;
			}
		}
		else if(step == 6)
		{
			u = 0;
//			v = 0;
			r= 0;
//			use_pidTheta = 0;
			process_RiceAppRoach2();
		}
		else if(step == 7)
		{
			AngleNow = -90;
			process_Accel_FloatingEnc6(-90, 0.6, 10000, 1.2, 0, 3,5);
			if(floatingEncCount>300){
				process_SubState = 0;
				step+=1;
			}
		}
		else if(step == 8)
		{
//			if(floatingEncCount>1000)
//			{
//				valve_ArmDown();
//			}
			process_Accel_FloatingEnc6(0, 1, 13000, 0.5, -95, 1.5, 5);
			if(floatingEncCount> 1400)
			{
				process_SubState = 0;
				step++;
			}
		}
		else if(step == 9)
		{

			process_Accel_FloatingEnc9(-90, 0.8, 10000, 1, -95, 1.5, 5);
			if(floatingEncCount>4800)
			{
				valve_ArmDown();
				step++;
			}

		}
		else if(step == 10)
		{
			process_Accel_FloatingEnc9(-90, 0, 0, 1, -95, 1, 5);
		}
		else if (step == 11)
		{
			Manual = 1;
			PlusControl = 2;
			if (GamePad.Up)
			{
				osDelay(200);
				if (GamePad.Up)
				{
					process_ResetFloatingEnc();
					// Set thong so quy hoach quy dao :
					PlusControl = 0;
					Manual = 0;
					// tha tay gap
					process_Error(1);
					valve_HandRelease();
					process_Error(0);
					osDelay(50);
					valve_ArmUp();
					osDelay(250);
					step ++;
					process_Count++;
				}
			}
		}

	 //Cap lua thu 2 4 6
		else if(step == 12)
		{
			AngleNow = 0;
			process_Accel_FloatingEnc6(0, 0.8, 500, 0.08, -95, 3, 5);
		}
		else if(step == 13)
		{
			process_Accel_FloatingEnc6(180-75, 1, 15000, 0.5, 5, 1.5, 5);
			if(floatingEncCount>8200)
			{
				process_SubState = 0;
				step++;
			}
		}
		else if(step == 14)
		{
			process_Accel_FloatingEnc6(180-15, 0.4, 100000, 0.08, 0, 3, 5);
			if((floatingEncCount>3500)&&(floatingEncCount<6000))
			{
				if(process_ThucHienGapLua() == true)
				{
					osDelay(1);
					if(process_ThucHienGapLua() == true)
					{

						u = 0;
						v = 0;
						r= 0;
						use_pidTheta = 0;
						BuzzerBeep_Start(2, 50, 50);
						step = 15;

					}
				}
			}

			if(floatingEncCount>6000)//3000
			{
				u = 0;
				v = 0;
				r= 0;
				use_pidTheta = 0;
		    	step = 15;
			}
		}
		else if(step == 15)
		{
			process_RunByAngle(90, 0.2);
			process_SSCheck++;
			if(process_SSCheck>10)
			{
				step++;
				process_SSCheck = 0;
			}
		}
		else if(step == 16)
		{
			u = 0;
			r= 0;
			process_RiceAppRoach2();
		}
		else if(step == 17)
		{
			AngleNow = -90;
			process_Accel_FloatingEnc6(-90, 0.6, 10000, 1.2, 0, 3,5);
			if(floatingEncCount>300){
				process_SubState = 0;
				step+=1;
			}
		}
		else if(step == 18)
		{
			process_Accel_FloatingEnc6(0, 1, 130000, 0.5, -95, 1.5, 5);

			if(floatingEncCount> 2200)
			{
				process_SubState = 0;
				step++;
			}
		}
		else if(step == 19)
		{
			process_Accel_FloatingEnc9(-90, 0.8, 10000, 1, -95, 1.5, 5);
			if(floatingEncCount>4500)
			{
				valve_ArmDown();
				step++;
			}
		}
		else if(step == 20)
		{
			process_Accel_FloatingEnc9(-90, 0, 0, 1, -95, 1, 5);

		}
		else if (step == 21)
		{
			Manual = 1;
			PlusControl = 2;
			if (GamePad.Up)
			{
				osDelay(200);
				if (GamePad.Up)
				{
					process_ResetFloatingEnc();
					// Set thong so quy hoach quy dao :
					PlusControl = 0;
					Manual = 0;
					// tha tay gap
					process_Error(1);
					valve_HandRelease();
					process_Error(0);
					osDelay(50);
					valve_ArmUp();
					osDelay(250);

					process_Count++;

					if(process_Count == 6)
					{
						step = 32;
					}
					else
					{
						step = 22;
					}

				}
			}
		}

		// Cap lua thu 3
		else if(step == 22)
		{
			AngleNow = 0;
			process_Accel_FloatingEnc6(0, 0.8, 1300, 0.08, 95, 3, 5);
		}
		else if(step == 23)
		{
			process_Accel_FloatingEnc6(180-80, 1, 15000, 0.5, 5, 1.5, 5);
			if(floatingEncCount>9000)
			{
				process_SubState = 0;
				step++;
			}
		}
		else if(step == 24)
		{
			process_Accel_FloatingEnc6(180-15, 0.4, 100000, 0.08, 0, 3, 5);
			if((floatingEncCount>3500)&&(floatingEncCount<5500))
			{
				if(process_ThucHienGapLua() == true)
				{
					osDelay(1);
					if(process_ThucHienGapLua() == true)
					{

						u = 0;
						v = 0;
						r= 0;
						use_pidTheta = 0;
						BuzzerBeep_Start(2, 50, 50);
						step = 25;

					}
				}
			}

			if(floatingEncCount>5500|| GamePad.Down)//3000
			{
				u = 0;
				v = 0;
				r= 0;
				use_pidTheta = 0;
		    	step = 25;
			}
		}
		else if(step == 25)
		{
			process_RunByAngle(90, 0.2);
			process_SSCheck++;
			if(process_SSCheck>10)
			{
				step++;
				process_SSCheck = 0;
			}
		}
		else if(step == 26)
		{
			u = 0;
//			v = 0;
			r= 0;
			process_RiceAppRoach2();
		}
		else if(step == 27)
		{
			AngleNow = -90;
			process_Accel_FloatingEnc6(-90, 0.6, 10000, 1.2, 0, 3,5);
			if(floatingEncCount>300){
				process_SubState = 0;
				step+=1;
			}
		}
		else if(step == 28)
		{
			process_Accel_FloatingEnc6(0, 1, 13000, 1, -95, 1.5, 5);
			if(floatingEncCount> 1200)
			{
				process_SubState = 0;
				step++;
			}
		}
		else if(step == 29)
		{

			process_Accel_FloatingEnc9(-90, 0.8, 10000, 1, -95, 1.5, 5);
			if(floatingEncCount>4800)
			{
				valve_ArmDown();
				step++;
			}
		}
		else if(step == 30)
		{
			process_Accel_FloatingEnc9(-90, 0, 0, 0.5, -95, 1, 5);

		}
		else if (step == 31)
		{
			Manual = 1;
			PlusControl = 2;
			if (GamePad.Up)
			{
				osDelay(200);
				if (GamePad.Up)
				{
					process_ResetFloatingEnc();
					// Set thong so quy hoach quy dao :
					PlusControl = 0;
					Manual = 0;
					// tha tay gap
					process_Error(1);
					valve_HandRelease();
					process_Error(0);
					osDelay(50);
					valve_ArmUp();
					osDelay(250);
					step = 12;
					process_Count++;
				}
			}
			// NUT LAY 6 LUA
//			if (GamePad.Left)
//			{
//				osDelay(200);
//				if(GamePad.Left)
//				{
//					process_ResetFloatingEnc();
//					// Set thong so quy hoach quy dao :
//					PlusControl = 0;
//					Manual = 0;
//					// tha tay gap
//					process_Error(1);
//					valve_HandRelease();
//					process_Error(0);
//					osDelay(50);
//					valve_ArmUp();
//					osDelay(250);
//					process_Count++;
//					if(process_Count == 3)
//					{
//						step = 32;
//					}
//
//				}
//			}

		}

		// Chay len khu 2
		else if(step == 32)
		{
			AngleNow = 0;
			if(process_Count == 6)
			{

				process_Accel_FloatingEnc6(0, 1, 1800, 0.08, -95, 3, 5);
			}
			if(process_Count == 3)
			{

				process_Accel_FloatingEnc6(0, 1, 11000, 0.08, -95, 3, 5);
			}
		}
		else if(step == 33)
		{
			process_Accel_FloatingEnc6(-88, 1, 14000, 0.1 , -95, 3, 5);
		}
		else if(step == 34)
		{
			process_Accel_FloatingEnc6(-180, 1, 5000, 0.5, 95, 2, 5);
		}
		else if(step == 35){
			ShootBallTime_Start(&GamePad);
			step++;
		}
		else if(step == 36){
			Manual = 1;
			PlusControl = 2;
			if(IsInShootBallTime() == false){
				PlusControl = 0;
				step += 1;
			}
		}
	}

///////////////////////////////////////////////////NUT BAM////////////////////////////////////////////////////////////

		if(GamePad.Triangle)
		{
			osDelay(300);
			if(GamePad.Triangle)
			{
				valve_ProcessBegin(ValveProcess_ShootBallTime_Reset);
			}
		}
		if(GamePad.Cross)
		{
			osDelay(300);
			if(GamePad.Cross)
			{
				valve_ArmDown();
				osDelay(500);
				valve_ArmUp();
				osDelay(500);
				valve_ArmDown();

			}
		}
		if (GamePad.Down && GamePad.Cross)	//Chuyen Sang Che Do GamePad
				{
			osDelay(100);
			if (GamePad.Down && GamePad.Cross)
					{
				Manual = 1;
				PlusControl = 0;
			}
		}
//
		if ((GamePad.Square == 1) && (GamePad.Right == 1))	// Xa day
				{
			osDelay(100);
			if ((GamePad.Square == 1) && (GamePad.Right == 1))
					{
				xaDay = 1;
			}
		}

//
		if (Manual == 1)
		{
			if(PlusControl == 0)
			{
				uControlX = -GamePad.XLeftCtr*2;
				uControlY = GamePad.YLeftCtr*1.7;
				uControlTheta = GamePad.XRightCtr*1.7;
			}

			if(PlusControl == 1)
			{
				process_PD_OnStrainghtPath();
				use_pidTheta = 1;
				u = -GamePad.XLeftCtr*0.8;
				v = GamePad.YLeftCtr*0.8;
//				r = GamePad.XRightCtr;
				process_Signal_RotationMatrixTransform2(u, v, r);
				if (absf(uControlX)>absf(uControlY))
				{
					uControlY = 0;
				}else if(absf(uControlX)<absf(uControlY))
				{
					uControlX = 0;
				}
			}
			if(PlusControl == 2)
			{
				uControlX = -GamePad.XLeftCtr*1;
				uControlY = GamePad.YLeftCtr*1;
				uControlTheta = GamePad.XRightCtr*1;
				if (absf(uControlX)>absf(uControlY))
				{
					uControlY = 0;
				}else if(absf(uControlX)<absf(uControlY))
				{
					uControlX = 0;
				}
			}
			if(PlusControl == 3)
			{
				uControlX = -GamePad.XLeftCtr*0.8;
				uControlY = GamePad.YLeftCtr*0.8;
				uControlTheta = GamePad.XRightCtr*1.6;
				if (absf(uControlX)>absf(uControlY))
				{
					uControlY = 0;
				}else if(absf(uControlX)<absf(uControlY))
				{
					uControlX = 0;
				}
			}
			if(PlusControl == 4)
			{
				uControlX = -GamePad.XLeftCtr*3;
				uControlY = GamePad.YLeftCtr*3;
				uControlTheta = GamePad.XRightCtr*1;
				if (absf(uControlX)>absf(uControlY))
				{
					uControlY = 0;
				}else if(absf(uControlX)<absf(uControlY))
				{
					uControlX = 0;
				}

			}
		}
		else if (Manual == 0) {
			process_Signal_RotationMatrixTransform(u, v, r);
		}
//	////////////////////////////////////////////////////////////////////////////////////////////////////////////
////				xTaskNotify(TaskInvKineHandle,1,eSetValueWithOverwrite);
		osDelay(DELTA_T * 1000);

	}
  /* USER CODE END OdometerHandle */
}

/* USER CODE BEGIN Header_TaskRunProcess */
/**
 * @brief Function implementing the TaskProcess thread.
 * @param argument: Not used
 * @retval None
 */

uint8_t processStep = 100;
/* USER CODE END Header_TaskRunProcess */
void TaskRunProcess(void const * argument)
{
  /* USER CODE BEGIN TaskRunProcess */
	/* Infinite loop */
	for (;;) {
//		__HAL_TIM_SET_COMPARE(&htim9,TIM_CHANNEL_1,pwm1);
//		__HAL_TIM_SET_COMPARE(&htim9,TIM_CHANNEL_2,pwm2);
//		__HAL_TIM_SET_COMPARE(&htim8,TIM_CHANNEL_3,pwm3);
//		__HAL_TIM_SET_COMPARE(&htim8, TIM_CHANNEL_4,pwm4);
		osDelay(100);
		}
  /* USER CODE END TaskRunProcess */
}

void HAL_TIM_PeriodElapsedCallback(TIM_HandleTypeDef *htim)
{
  /* USER CODE BEGIN Callback 0 */
	RB1_GunIncreaseTickTimerInInterrupt();
	RB1_UpdateAccelTickInInterrupt();
  /* USER CODE END Callback 0 */
  if (htim->Instance == TIM14) {
    HAL_IncTick();
  }
}

void Error_Handler(void)
{
__disable_irq();
while (1) {
}
}
